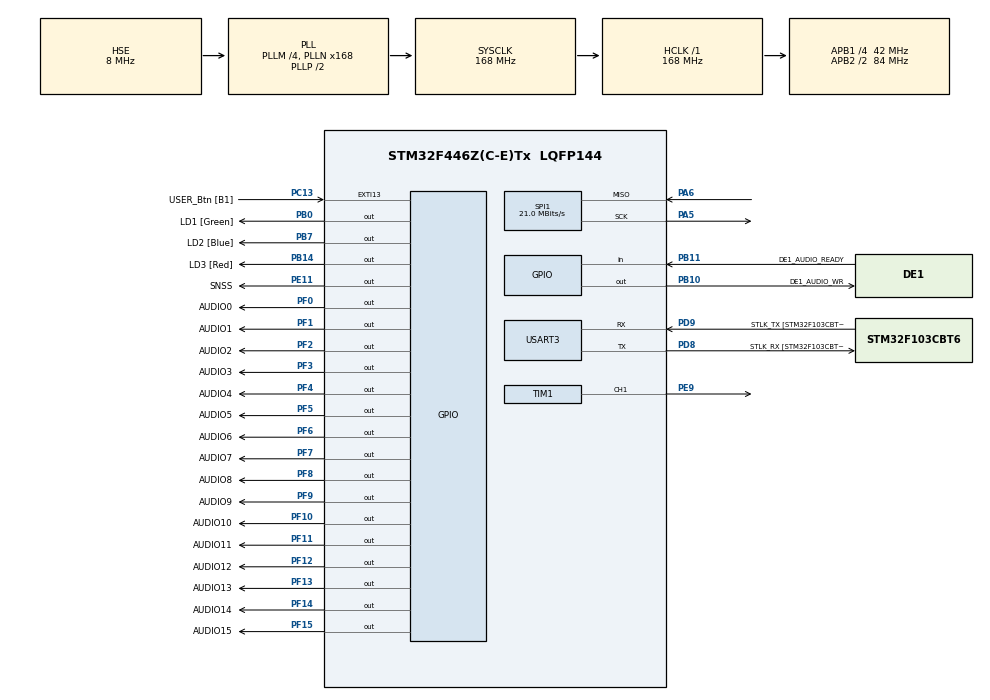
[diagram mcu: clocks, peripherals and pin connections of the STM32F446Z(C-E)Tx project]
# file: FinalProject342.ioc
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Mcu.Family=STM32F4
Mcu.Name=STM32F446Z(C-E)Tx
Mcu.Package=LQFP144
NVIC.PriorityGroup=NVIC_PRIORITYGROUP_4
PA10.GPIO_Label=USB_ID
PA10.Signal=USB_OTG_FS_ID
PA11.GPIO_Label=USB_DM
PA11.Signal=USB_OTG_FS_DM
PA12.GPIO_Label=USB_DP
PA12.Signal=USB_OTG_FS_DP
PA13.GPIO_Label=TMS
PA13.Mode=Serial_Wire
PA13.Signal=SYS_JTMS-SWDIO
PA14.GPIO_Label=TCK
PA14.Mode=Serial_Wire
PA14.Signal=SYS_JTCK-SWCLK
PA5.Mode=RX_Only_Simplex_Unidirect_Master
PA5.Signal=SPI1_SCK
PA6.Mode=RX_Only_Simplex_Unidirect_Master
PA6.Signal=SPI1_MISO
PA8.GPIO_Label=USB_SOF [TP1]
PA8.Signal=USB_OTG_FS_SOF
PA9.GPIO_Label=USB_VBUS
PA9.Signal=USB_OTG_FS_VBUS
PB0.GPIO_Label=LD1 [Green]
PB0.Signal=GPIO_Output
PB10.GPIO_Label=DE1_AUDIO_WR
PB10.GPIO_ModeDefaultOutputPP=GPIO_MODE_OUTPUT_OD
PB10.GPIO_PuPd=GPIO_NOPULL
PB10.GPIO_Speed=GPIO_SPEED_FREQ_VERY_HIGH
PB10.Signal=GPIO_Output
PB11.GPIO_Label=DE1_AUDIO_READY
PB11.Signal=GPIO_Input
PB14.GPIO_Label=LD3 [Red]
PB14.Signal=GPIO_Output
PB7.GPIO_Label=LD2 [Blue]
PB7.Signal=GPIO_Output
PC13.GPIO_Label=USER_Btn [B1]
PC13.Signal=GPXTI13
PC14-OSC32_IN.Mode=LSE-External-Oscillator
PC14-OSC32_IN.Signal=RCC_OSC32_IN
PC15-OSC32_OUT.Mode=LSE-External-Oscillator
PC15-OSC32_OUT.Signal=RCC_OSC32_OUT
PD8.GPIO_Label=STLK_RX [STM32F103CBT6_PA3]
PD8.Mode=Asynchronous
PD8.Signal=USART3_TX
PD9.GPIO_Label=STLK_TX [STM32F103CBT6_PA2]
PD9.Mode=Asynchronous
PD9.Signal=USART3_RX
PE11.GPIO_Label=SNSS
PE11.GPIO_ModeDefaultOutputPP=GPIO_MODE_OUTPUT_OD
PE11.GPIO_PuPd=GPIO_NOPULL
PE11.GPIO_Speed=GPIO_SPEED_FREQ_LOW
PE11.Signal=GPIO_Output
PE9.Signal=S_TIM1_CH1
PF0.GPIO_Label=AUDIO0
PF0.GPIO_ModeDefaultOutputPP=GPIO_MODE_OUTPUT_OD
PF0.GPIO_PuPd=GPIO_NOPULL
PF0.GPIO_Speed=GPIO_SPEED_FREQ_VERY_HIGH
PF0.Signal=GPIO_Output
PF1.GPIO_Label=AUDIO1
PF1.GPIO_ModeDefaultOutputPP=GPIO_MODE_OUTPUT_OD
PF1.GPIO_PuPd=GPIO_NOPULL
PF1.GPIO_Speed=GPIO_SPEED_FREQ_VERY_HIGH
PF1.Signal=GPIO_Output
PF10.GPIO_Label=AUDIO10
PF10.GPIO_ModeDefaultOutputPP=GPIO_MODE_OUTPUT_OD
PF10.GPIO_PuPd=GPIO_NOPULL
PF10.GPIO_Speed=GPIO_SPEED_FREQ_VERY_HIGH
PF10.Signal=GPIO_Output
PF11.GPIO_Label=AUDIO11
PF11.GPIO_ModeDefaultOutputPP=GPIO_MODE_OUTPUT_OD
PF11.GPIO_PuPd=GPIO_NOPULL
PF11.GPIO_Speed=GPIO_SPEED_FREQ_VERY_HIGH
PF11.Signal=GPIO_Output
PF12.GPIO_Label=AUDIO12
PF12.GPIO_ModeDefaultOutputPP=GPIO_MODE_OUTPUT_OD
PF12.GPIO_PuPd=GPIO_NOPULL
PF12.GPIO_Speed=GPIO_SPEED_FREQ_VERY_HIGH
PF12.Signal=GPIO_Output
PF13.GPIO_Label=AUDIO13
PF13.GPIO_ModeDefaultOutputPP=GPIO_MODE_OUTPUT_OD
PF13.GPIO_PuPd=GPIO_NOPULL
PF13.GPIO_Speed=GPIO_SPEED_FREQ_VERY_HIGH
PF13.Signal=GPIO_Output
PF14.GPIO_Label=AUDIO14
PF14.GPIO_ModeDefaultOutputPP=GPIO_MODE_OUTPUT_OD
PF14.GPIO_PuPd=GPIO_NOPULL
PF14.GPIO_Speed=GPIO_SPEED_FREQ_VERY_HIGH
PF14.Signal=GPIO_Output
PF15.GPIO_Label=AUDIO15
PF15.GPIO_ModeDefaultOutputPP=GPIO_MODE_OUTPUT_OD
PF15.GPIO_PuPd=GPIO_NOPULL
PF15.GPIO_Speed=GPIO_SPEED_FREQ_VERY_HIGH
PF15.Signal=GPIO_Output
PF2.GPIO_Label=AUDIO2
PF2.GPIO_ModeDefaultOutputPP=GPIO_MODE_OUTPUT_OD
PF2.GPIO_PuPd=GPIO_NOPULL
PF2.GPIO_Speed=GPIO_SPEED_FREQ_VERY_HIGH
PF2.Signal=GPIO_Output
PF3.GPIO_Label=AUDIO3
PF3.GPIO_ModeDefaultOutputPP=GPIO_MODE_OUTPUT_OD
PF3.GPIO_PuPd=GPIO_NOPULL
PF3.GPIO_Speed=GPIO_SPEED_FREQ_VERY_HIGH
PF3.Signal=GPIO_Output
PF4.GPIO_Label=AUDIO4
PF4.GPIO_ModeDefaultOutputPP=GPIO_MODE_OUTPUT_OD
PF4.GPIO_PuPd=GPIO_NOPULL
PF4.GPIO_Speed=GPIO_SPEED_FREQ_VERY_HIGH
PF4.Signal=GPIO_Output
PF5.GPIO_Label=AUDIO5
PF5.GPIO_ModeDefaultOutputPP=GPIO_MODE_OUTPUT_OD
PF5.GPIO_PuPd=GPIO_NOPULL
PF5.GPIO_Speed=GPIO_SPEED_FREQ_VERY_HIGH
PF5.Signal=GPIO_Output
PF6.GPIO_Label=AUDIO6
PF6.GPIO_ModeDefaultOutputPP=GPIO_MODE_OUTPUT_OD
PF6.GPIO_PuPd=GPIO_NOPULL
PF6.GPIO_Speed=GPIO_SPEED_FREQ_VERY_HIGH
PF6.Signal=GPIO_Output
PF7.GPIO_Label=AUDIO7
PF7.GPIO_ModeDefaultOutputPP=GPIO_MODE_OUTPUT_OD
PF7.GPIO_PuPd=GPIO_NOPULL
PF7.GPIO_Speed=GPIO_SPEED_FREQ_VERY_HIGH
PF7.Signal=GPIO_Output
PF8.GPIO_Label=AUDIO8
PF8.GPIO_ModeDefaultOutputPP=GPIO_MODE_OUTPUT_OD
PF8.GPIO_PuPd=GPIO_NOPULL
PF8.GPIO_Speed=GPIO_SPEED_FREQ_VERY_HIGH
PF8.Signal=GPIO_Output
PF9.GPIO_Label=AUDIO9
PF9.GPIO_ModeDefaultOutputPP=GPIO_MODE_OUTPUT_OD
PF9.GPIO_PuPd=GPIO_NOPULL
PF9.GPIO_Speed=GPIO_SPEED_FREQ_VERY_HIGH
PF9.Signal=GPIO_Output
PH0-OSC_IN.GPIO_Label=MCO [STM32F103CBT6_PA8]
PH0-OSC_IN.Mode=HSE-External-Clock-Source
PH0-OSC_IN.Signal=RCC_OSC_IN
PH1-OSC_OUT.Mode=HSE-External-Clock-Source
PH1-OSC_OUT.Signal=RCC_OSC_OUT
ProjectManager.HeapSize=0x200
ProjectManager.StackSize=0x400
ProjectManager.TargetToolchain=STM32CubeIDE
RCC.48MHZClocksFreq_Value=24000000
RCC.AHBFreq_Value=168000000
RCC.APB1CLKDivider=RCC_HCLK_DIV4
RCC.APB1Freq_Value=42000000
RCC.APB1TimFreq_Value=84000000
RCC.APB2CLKDivider=RCC_HCLK_DIV2
RCC.APB2Freq_Value=84000000
RCC.APB2TimFreq_Value=168000000
RCC.CortexFreq_Value=168000000
RCC.HCLKFreq_Value=168000000
RCC.HSE_VALUE=8000000
RCC.HSI_VALUE=16000000
RCC.PLLM=4
RCC.PLLMUL=RCC_PLL_MUL9
RCC.PLLN=168
RCC.PLLQ=7
RCC.PLLSourceVirtual=RCC_PLLSOURCE_HSE
RCC.PRESCALERUSB=RCC_USBCLKSOURCE_PLL_DIV1_5
RCC.SYSCLKFreq_VALUE=168000000
RCC.SYSCLKSource=RCC_SYSCLKSOURCE_PLLCLK
RCC.SYSCLKSourceVirtual=RCC_SYSCLKSOURCE_PLLCLK
RCC.USBFreq_Value=48000000
RCC.VCOOutputFreq_Value=336000000
SH.S_TIM1_CH1.0=TIM1_CH1,PWM Generation1 CH1
SPI1.BaudRatePrescaler=SPI_BAUDRATEPRESCALER_4
SPI1.CalculateBaudRate=21.0 MBits/s
SPI1.DataSize=SPI_DATASIZE_8BIT
SPI1.Direction=SPI_DIRECTION_2LINES_RXONLY
SPI1.FirstBit=SPI_FIRSTBIT_MSB
SPI1.Mode=SPI_MODE_MASTER
SPI1.VirtualType=VM_MASTER
TIM1.AutoReloadPreload=TIM_AUTORELOAD_PRELOAD_ENABLE
TIM1.Channel-PWM\ Generation1\ CH1=TIM_CHANNEL_1
TIM1.Period=5
TIM1.Pulse-PWM\ Generation1\ CH1=10
USART3.VirtualMode=VM_ASYNC
VP_TIM1_VS_ClockSourceINT.Mode=Internal
board=NUCLEO-F446ZE

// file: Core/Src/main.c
/* USER CODE BEGIN Header */
/**
  ******************************************************************************
  * @file           : main.c
  * @brief          : Main program body
  ******************************************************************************
  * @attention
  *
  * Copyright (c) 2023 STMicroelectronics.
  * All rights reserved.
  *
  * This software is licensed under terms that can be found in the LICENSE file
  * in the root directory of this software component.
  * If no LICENSE file comes with this software, it is provided AS-IS.
  *
  ******************************************************************************
  */
/* USER CODE END Header */
#include "main.h"

/* USER CODE BEGIN Includes */
#include <stdio.h>
#include <string.h>
//#include "usb_host.h"
//#include "fatfs.h"
//#include "usb_conf.h"
/* USER CODE END Includes */

SPI_HandleTypeDef hspi1;

TIM_HandleTypeDef htim1;

UART_HandleTypeDef huart3;

/* USER CODE BEGIN PV */
static const uint16_t ding_pcm[7988] =
{
    0x0000, 0x0000, 0x0000, 0x0000, 0x0001, 0xFFFE, 0x0002, 0xFFFE, 0x0001, 0x0000, 0x0001, 0xFFFD, 0x0003, 0xFFFE, 0x0001, 0x0000, 0xFFFF, 0x0001, 0x0000, 0x0000, 0x0000, 0x0000, 0xFFFF, 0x0002, 0xFFFE,
    0x0003, 0xFFFD, 0x0002, 0xFFFE, 0x0002, 0xFFFE, 0x0002, 0xFFFF, 0xFFFF, 0x0003, 0xFFFC, 0x0003, 0xFFFF, 0x0000, 0x0000, 0x0001, 0xFFFE, 0x0002, 0xFFFE, 0x0002, 0xFFFF, 0x0000, 0x0000, 0xFFFF, 0x0002,
    0xFFFE, 0x0002, 0xFFFE, 0x0001, 0x0001, 0xFFFE, 0x0002, 0xFFFE, 0x0002, 0xFFFE, 0x0003, 0xFFFC, 0x0004, 0xFFFD, 0x0001, 0x0001, 0xFFFE, 0x0002, 0xFFFF, 0x0000, 0x0000, 0x0001, 0xFFFE, 0x0003, 0xFFFD,
    0x0002, 0xFFFF, 0x0001, 0xFFFF, 0x0000, 0x0001, 0xFFFF, 0x0001, 0xFFFF, 0x0000, 0x0001, 0xFFFF, 0x0001, 0xFFFF, 0x0001, 0xFFFE, 0x0002, 0x0000, 0xFFFE, 0x0003, 0xFFFC, 0x0004, 0xFFFD, 0x0002, 0xFFFF,
    0x0000, 0x0001, 0xFFFE, 0x0003, 0xFFFD, 0x0002, 0xFFFF, 0x0001, 0xFFFF, 0x0000, 0x0001, 0xFFFF, 0x0001, 0xFFFF, 0x0000, 0x0001, 0xFFFF, 0x0001, 0xFFFF, 0x0001, 0xFFFF, 0x0001, 0xFFFE, 0x0003, 0xFFFD,
    0x0002, 0x0000, 0xFFFE, 0x0003, 0xFFFD, 0x0003, 0xFFFD, 0x0004, 0xFFFB, 0x0004, 0xFFFE, 0x0001, 0xFFFF, 0x0000, 0x0001, 0xFFFF, 0x0001, 0xFFFF, 0xFFFF, 0x0003, 0xFFFE, 0x0001, 0xFFFF, 0x0000, 0x0001,
    0x0000, 0xFFFF, 0x0001, 0xFFFE, 0x0003, 0xFFFE, 0x0000, 0x0001, 0xFFFF, 0x0000, 0x0002, 0xFFFD, 0x0002, 0xFFFF, 0x0001, 0xFFFF, 0x0001, 0xFFFF, 0x0001, 0xFFFF, 0x0001, 0x0000, 0xFFFF, 0x0002, 0xFFFE,
    0x0002, 0xFFFF, 0xFFFF, 0x0002, 0xFFFE, 0x0002, 0xFFFE, 0x0002, 0xFFFF, 0x0000, 0x0001, 0xFFFE, 0x0002, 0xFFFF, 0x0000, 0x0001, 0xFFFE, 0x0002, 0xFFFE, 0x0001, 0x0000, 0xFFFF, 0x0002, 0xFFFE, 0x0001,
    0x0001, 0xFFFD, 0x0004, 0xFFFB, 0x0005, 0xFFFB, 0x0005, 0xFFFB, 0x0005, 0xFFFB, 0x0005, 0xFFFC, 0x0003, 0xFFFD, 0x0003, 0xFFFD, 0x0003, 0xFFFE, 0x0001, 0x0000, 0x0000, 0x0000, 0x0001, 0xFFFF, 0x0002,
    0xFFFF, 0x0001, 0xFFFF, 0x0001, 0xFFFE, 0x0002, 0xFFFE, 0x0003, 0xFFFD, 0x0003, 0xFFFC, 0x0006, 0xFFFB, 0x0004, 0xFFFC, 0x0003, 0xFFFF, 0x0000, 0x0000, 0x0001, 0xFFFE, 0x0002, 0xFFFE, 0x0000, 0x0002,
    0xFFFC, 0x0003, 0xFFFD, 0x0004, 0xFFFB, 0x0004, 0xFFFD, 0x0003, 0xFFFD, 0x0002, 0x0000, 0xFFFF, 0x0000, 0xFFFF, 0x0002, 0xFFFD, 0x0003, 0xFFFC, 0x0004, 0xFFFC, 0x0002, 0xFFFF, 0x0001, 0x0001, 0xFFFE,
    0x0002, 0xFFFE, 0x0001, 0xFFFE, 0x0001, 0xFFFF, 0x0001, 0xFFFF, 0x0001, 0xFFFE, 0x0003, 0xFFFE, 0xFFFF, 0x0001, 0xFFFF, 0x0000, 0x0001, 0xFFFE, 0x0003, 0xFFFE, 0x0000, 0x0001, 0xFFFF, 0x0001, 0xFFFF,
    0x0000, 0x0002, 0xFFFE, 0x0000, 0x0000, 0x0000, 0x0000, 0x0000, 0x0000, 0x0002, 0x0000, 0x0001, 0xFFFF, 0x0001, 0xFFFF, 0x0001, 0x0000, 0x0001, 0xFFFF, 0x0001, 0x0002, 0xFFFD, 0x0003, 0xFFFF, 0x0001,
    0x0002, 0xFFFF, 0x0004, 0xFFFD, 0x0002, 0x0001, 0xFFFE, 0x0004, 0xFFFC, 0x0003, 0x0000, 0x0000, 0x0000, 0x0001, 0xFFFD, 0x0003, 0xFFFD, 0x0002, 0x0000, 0xFFFE, 0x0001, 0xFFFF, 0x0001, 0xFFFF, 0x0000,
    0xFFFF, 0xFFFF, 0x0001, 0xFFFE, 0x0000, 0x0000, 0x0001, 0xFFFF, 0x0002, 0xFFFF, 0x0002, 0x0000, 0xFFFF, 0x0002, 0xFFFE, 0x0003, 0xFFFE, 0x0001, 0x0000, 0x0002, 0xFFFE, 0x0003, 0xFFFE, 0x0001, 0x0000,
    0xFFFF, 0x0001, 0x0000, 0xFFFF, 0xFFFE, 0x0002, 0xFFFF, 0x0001, 0xFFFF, 0xFFFE, 0x0001, 0xFFFF, 0x0001, 0xFFFF, 0xFFFE, 0x0002, 0xFFFC, 0x0003, 0xFFFC, 0x0001, 0x0000, 0xFFFD, 0x0002, 0xFFFE, 0x0002,
    0xFFFF, 0x0001, 0xFFFC, 0x0006, 0xFFFA, 0x0004, 0xFFFF, 0xFFFE, 0x0005, 0xFFFB, 0x0006, 0xFFFC, 0x0005, 0xFFFF, 0x0000, 0x0002, 0xFFFC, 0x0003, 0xFFFF, 0xFFFE, 0x0003, 0xFFFB, 0x0004, 0xFFFD, 0x0000,
    0xFFFF, 0x0002, 0xFFFB, 0x0004, 0xFFFA, 0x0002, 0xFFFE, 0xFFFE, 0x0002, 0xFFFD, 0x0001, 0xFFFE, 0x0001, 0xFFFE, 0xFFFF, 0xFFFE, 0x0002, 0x0001, 0xFFFF, 0x0001, 0x0002, 0xFFFD, 0x0002, 0x0003, 0xFFFC,
    0x0005, 0xFFFB, 0x0005, 0xFFFD, 0x0003, 0xFFFD, 0x0002, 0xFFFE, 0x0002, 0x0002, 0x0001, 0x0000, 0x0003, 0xFFFF, 0x0001, 0xFFFD, 0x0002, 0x0000, 0x0002, 0xFFFC, 0x0005, 0xFFFC, 0x0004, 0xFFFC, 0x0004,
    0xFFFE, 0x0004, 0xFFFF, 0x0001, 0x0000, 0x0000, 0x0000, 0x0000, 0x0002, 0xFFFD, 0x0002, 0x0001, 0x0001, 0x0001, 0xFFFF, 0xFFFF, 0x0000, 0xFFFF, 0x0001, 0xFFFE, 0x0000, 0x0002, 0x0001, 0x0001, 0xFFFE,
    0x0001, 0xFFFF, 0x0000, 0x0000, 0x0002, 0xFFFF, 0xFFFD, 0xFFFF, 0x0004, 0xFFFC, 0x0004, 0xFFFC, 0x0005, 0xFFFC, 0x0003, 0xFFFF, 0x0000, 0xFFFE, 0x0000, 0x0003, 0xFFFA, 0x0003, 0xFFFC, 0x0001, 0xFFFE,
    0x0001, 0xFFFD, 0x0002, 0xFFFE, 0xFFFF, 0xFFFC, 0x0004, 0xFFFF, 0xFFFF, 0x0001, 0xFFFE, 0x0003, 0xFFFF, 0x0000, 0xFFFD, 0x0000, 0xFFFC, 0x0001, 0x0000, 0xFFFF, 0x0001, 0xFFFF, 0x0003, 0xFFFF, 0x0004,
    0xFFFE, 0x0001, 0x0001, 0xFFFB, 0x0004, 0xFFFE, 0x0000, 0x0001, 0x0000, 0xFFFE, 0x0001, 0x0001, 0x0001, 0x0000, 0x0001, 0xFFFE, 0x0004, 0xFFFB, 0x0004, 0xFFFE, 0x0000, 0x0003, 0xFFFD, 0x0003, 0xFFFE,
    0x0000, 0xFFFF, 0xFFFF, 0xFFFF, 0xFFFF, 0x0000, 0xFFFE, 0x0001, 0x0001, 0xFFFF, 0xFFFD, 0x0003, 0xFFFD, 0x0000, 0xFFFF, 0x0001, 0x0000, 0xFFFF, 0x0002, 0xFFFE, 0xFFFF, 0xFFFF, 0xFFFC, 0x0004, 0xFFFC,
    0x0004, 0xFFFE, 0x0002, 0xFFFF, 0xFFFF, 0x0000, 0xFFFE, 0xFFFF, 0x0001, 0xFFFF, 0x0002, 0xFFFB, 0x0003, 0xFFFC, 0x0002, 0xFFFD, 0x0002, 0xFFFD, 0xFFFE, 0x0001, 0x0001, 0x0001, 0x0001, 0x0002, 0xFFFF,
    0x0000, 0x0002, 0xFFFF, 0xFFFF, 0x0002, 0xFFFD, 0x0002, 0x0000, 0xFFFF, 0xFFFE, 0x0003, 0xFFFB, 0x0006, 0xFFFA, 0x0002, 0xFFFB, 0x0004, 0xFFFA, 0x0000, 0x0002, 0xFFFE, 0x0002, 0xFFFE, 0x0000, 0x0003,
    0xFFFF, 0x0001, 0x0000, 0xFFFD, 0x0002, 0xFFFF, 0x0001, 0x0000, 0xFFFE, 0x0001, 0xFFFF, 0x0000, 0xFFFE, 0xFFFF, 0xFFFF, 0x0000, 0xFFFF, 0xFFFF, 0x0002, 0xFFFD, 0x0000, 0xFFFD, 0x0001, 0xFFFD, 0x0002,
    0xFFFF, 0x0001, 0x0001, 0xFFFD, 0x0004, 0xFFFC, 0xFFFE, 0x0001, 0xFFFE, 0x0000, 0xFFFE, 0xFFFF, 0x0002, 0x0000, 0x0000, 0x0001, 0xFFFF, 0x0003, 0xFFFF, 0x0003, 0x0000, 0x0001, 0xFFFD, 0x0000, 0xFFFF,
    0x0001, 0xFFFF, 0x0001, 0xFFFE, 0x0001, 0xFFFE, 0x0004, 0xFFFF, 0x0001, 0xFFFF, 0xFFFE, 0x0002, 0x0000, 0xFFFF, 0x0000, 0xFFFE, 0x0000, 0x0000, 0x0000, 0x0001, 0x0000, 0xFFFE, 0x0000, 0x0000, 0x0000,
    0xFFFF, 0xFFFF, 0xFFFD, 0x0003, 0xFFFD, 0x0001, 0xFFFE, 0x0001, 0xFFFC, 0x0001, 0x0000, 0xFFFC, 0x0001, 0xFFFE, 0x0000, 0x0003, 0xFFFD, 0x0002, 0xFFFF, 0x0001, 0xFFFC, 0x0003, 0xFFFE, 0x0000, 0x0003,
    0xFFFC, 0x0003, 0xFFFD, 0x0004, 0xFFFC, 0xFFFB, 0x0004, 0xFFFE, 0x0002, 0x0000, 0x0007, 0xFFFC, 0xFFFE, 0xFFFF, 0x0001, 0x0001, 0x0005, 0x0003, 0x0001, 0xFFFF, 0x0005, 0xFFFD, 0x0007, 0xFFF6, 0x0003,
    0x0001, 0x0004, 0xFFFA, 0x0000, 0x0005, 0x0004, 0x0001, 0x0001, 0xFFFD, 0x0009, 0xFFFE, 0xFFFE, 0x0001, 0xFFF7, 0x000B, 0xFFF5, 0x000A, 0xFFF9, 0xFFFA, 0xFFFB, 0x0007, 0xFFFC, 0x0005, 0xFFFA, 0x0007,
    0xFFF4, 0x0001, 0x000C, 0xFF73, 0xFF92, 0xFF77, 0x001C, 0xFEED, 0xFFAA, 0xFFDC, 0xFFA5, 0x0031, 0xFF34, 0xFFC3, 0xFF52, 0xFFC3, 0xFED8, 0xFFFB, 0xFF90, 0xFF25, 0xFF6D, 0xFEE3, 0xFFA0, 0xFEA2, 0xFFED,
    0xFF21, 0xFF4F, 0xFFA4, 0xFF7A, 0xFFA8, 0xFF48, 0xFFFF, 0xFF71, 0xFF1C, 0x0004, 0xFF7F, 0xFF7D, 0xFF9B, 0xFF74, 0xFF9F, 0xFF7C, 0xFF7A, 0xFE8E, 0x0017, 0xFFAF, 0xFF90, 0xFF52, 0x000A, 0xFFF6, 0xFF59,
    0xFF78, 0xFFBF, 0x0004, 0xFE94, 0x0028, 0xFF7A, 0xFF91, 0xFF76, 0xFFA7, 0xFF55, 0xFFCF, 0xFF29, 0xFFBA, 0x0063, 0xFF38, 0xFF15, 0x000D, 0x0002, 0xFF79, 0xFF41, 0xFFAC, 0x0046, 0xFE81, 0x001C, 0xFEE4,
    0x0027, 0xFF8A, 0xFF78, 0xFF4A, 0xFFAB, 0xFEFF, 0xFFBC, 0xFF8A, 0xFF40, 0x0019, 0xFFD1, 0xFF7E, 0xFF22, 0xFEFC, 0xFF3D, 0x00C9, 0xFE89, 0xFF31, 0xFEE2, 0x0128, 0xFE70, 0x0010, 0xFEC3, 0x01FC, 0xFD8A,
    0x002A, 0xFE97, 0x0096, 0xFEAC, 0xFF9F, 0xFF4B, 0xFED0, 0x0068, 0xFE72, 0x00D0, 0xFEF7, 0x00B5, 0xFE16, 0x01CB, 0xFCDE, 0x01AF, 0xFCE4, 0x02DA, 0xFBFC, 0x0418, 0xFAF5, 0x04E9, 0xFA28, 0x0387, 0xFBB4,
    0x04FE, 0xF9F1, 0x02A3, 0xFE21, 0x00CE, 0xFDBC, 0x06FC, 0x0844, 0xD05E, 0x2FCE, 0x03FF, 0xF405, 0xDB35, 0x24E3, 0xECAF, 0x0E47, 0x0B09, 0xDDF7, 0x1F19, 0xEDE2, 0xFF7D, 0x1697, 0xDBA4, 0x1C27, 0x02AF,
    0xC562, 0x51D8, 0xC22D, 0x2028, 0xF44D, 0xF05A, 0x34EE, 0xDA01, 0xDE82, 0x448B, 0xE894, 0xD11F, 0x28E8, 0xF801, 0x1416, 0xE83E, 0xEF2E, 0x3378, 0xE1A7, 0xDB36, 0x40E8, 0xC929, 0x1EB1, 0xF75C, 0xEDBA,
    0x23F8, 0xF612, 0xE5A1, 0x1B0D, 0x026B, 0xE66F, 0x0E00, 0xEC3A, 0x205E, 0xFB38, 0xD6D7, 0x3B1E, 0xF2DB, 0xD3F4, 0x2E16, 0xE386, 0x0BC8, 0xF625, 0xF72B, 0x1D46, 0xFAB6, 0xDF74, 0x2965, 0xEE17, 0xEF52,
    0x228B, 0xD258, 0x1EE3, 0x0389, 0xD544, 0x3273, 0xF084, 0xF100, 0x1F25, 0xDA9A, 0x21D8, 0xEB74, 0xE53F, 0x2FFF, 0xE949, 0xED27, 0x2CC4, 0xE1B9, 0x0E49, 0xFDC3, 0xE62C, 0x2771, 0xE12E, 0xF56C, 0x255C,
    0xDEE1, 0x0E51, 0x0DBF, 0xE2A9, 0x1D0B, 0xECA1, 0xF4C9, 0x2350, 0xE7A8, 0xEA56, 0x310B, 0xD49C, 0x2173, 0xF4EB, 0xE5CE, 0x3117, 0xDEE2, 0xE6D7, 0x2B8E, 0xEADB, 0xF663, 0x1A3F, 0xE21E, 0x2CB6, 0xE4E5,
    0xE55C, 0x3651, 0xDCF8, 0xEBC2, 0x2B6B, 0xDB1F, 0x218E, 0xEF9D, 0xEBD2, 0x3079, 0xE567, 0xEB06, 0x231B, 0xE563, 0x02B5, 0x0D4E, 0xDD34, 0x2FF8, 0xECDD, 0xE76C, 0x324F, 0xDF56, 0xFA29, 0x0F8F, 0xE36E,
    0x2809, 0xE21C, 0xF748, 0x2D2B, 0xDE39, 0xF853, 0x24BA, 0xDC2A, 0x0E3C, 0xFC03, 0xE9C7, 0x2CE9, 0xE127, 0xF544, 0x30A6, 0xD45E, 0x0E40, 0x0974, 0xDDE7, 0x2B54, 0xDBE3, 0xF471, 0x31EB, 0xDC63, 0xFF24,
    0x2474, 0xD5DA, 0x2192, 0xECC5, 0xE6A6, 0x36B3, 0xD1A5, 0xFE07, 0x2E19, 0xD393, 0x1AA9, 0xF7F9, 0xECD4, 0x2DAA, 0xD822, 0xF32F, 0x2C34, 0xDCBC, 0x037A, 0x16FC, 0xDEB1, 0x2AC8, 0xE72E, 0xECB8, 0x2C24,
    0xDD27, 0xF55A, 0x23F3, 0xDB40, 0x1F25, 0xFCDE, 0xE3C3, 0x2C55, 0xE84C, 0xEC9E, 0x1F26, 0xE41A, 0x0886, 0x0BE8, 0xDEE1, 0x3293, 0xE4CF, 0xEFFB, 0x22CE, 0xE714, 0xFC2C, 0x1793, 0xDAB7, 0x1CD1, 0xF9F3,
    0xE914, 0x3240, 0xDC7C, 0xFFA8, 0x23E9, 0xCDCD, 0x192A, 0x0556, 0xD1EB, 0x3DF0, 0xDAAB, 0xFD93, 0x2AE2, 0xD47D, 0x0FF0, 0x0A8D, 0xD37F, 0x333C, 0xE4A3, 0xE5CB, 0x40B1, 0xCFBF, 0x04D2, 0x22D5, 0xD2FD,
    0x244A, 0xF1AF, 0xE32A, 0x342F, 0xCFC9, 0x074B, 0x1EA8, 0xDC93, 0x162B, 0x0BC2, 0xDBC4, 0x234F, 0xEC5C, 0xEAD4, 0x273B, 0xDAA4, 0x0EB3, 0x12DA, 0xE18B, 0x23AE, 0xEDFA, 0xED70, 0x2425, 0xE276, 0xFA36,
    0x1CF2, 0xE2F8, 0x0C40, 0x0A63, 0xE8FB, 0x23FF, 0xE394, 0xFD0C, 0x1F89, 0xD507, 0x0A4A, 0x1146, 0xE064, 0x1FB3, 0xF6E0, 0xF392, 0x2360, 0xDF5E, 0xFFCC, 0x146F, 0xD95C, 0x1DC5, 0xFC20, 0xE31A, 0x3639,
    0xDB86, 0xFDFE, 0x26D5, 0xCE84, 0x1830, 0x042E, 0xDFD4, 0x27EC, 0xE074, 0xFFE8, 0x28C1, 0xCF49, 0x1895, 0x15B2, 0xCD43, 0x26B3, 0xEE23, 0xEE49, 0x263E, 0xDBBC, 0x10CD, 0x1544, 0xDA60, 0x223C, 0xF215,
    0xEA2C, 0x23E4, 0xDF29, 0x012B, 0x1A60, 0xE4D6, 0x0A5B, 0x0C9F, 0xE660, 0x1B48, 0xEC5E, 0xF86F, 0x1CF2, 0xD949, 0x0C21, 0x13F2, 0xE136, 0x1895, 0xFCDE, 0xF1EC, 0x18FF, 0xE4BC, 0x01F8, 0x10AF, 0xE1DF,
    0x164F, 0x0220, 0xEA94, 0x22A6, 0xE811, 0xF8A9, 0x1DDB, 0xDC07, 0x0BCF, 0x0965, 0xE560, 0x21B9, 0xE9F8, 0xFB7E, 0x229B, 0xD975, 0x0B87, 0x13B0, 0xD8A7, 0x1ABA, 0xF83E, 0xEE0F, 0x23A8, 0xE298, 0x07FF,
    0x15DA, 0xD958, 0x1A02, 0xFC1C, 0xE47B, 0x229C, 0xE966, 0xFCAB, 0x1D80, 0xE3DD, 0x0944, 0x0A6E, 0xE5A7, 0x1922, 0xF03A, 0xF544, 0x1C8C, 0xE5A0, 0x0246, 0x18B9, 0xE192, 0x11EC, 0x01E3, 0xECEA, 0x1540,
    0xECD9, 0xFD0C, 0x1382, 0xEB49, 0x09AD, 0x0D19, 0xE823, 0x18F4, 0xF303, 0xF0AF, 0x17B0, 0xEBA6, 0xFFDB, 0x11A6, 0xE822, 0x17A2, 0xF6C6, 0xF4B4, 0x1B5B, 0xE482, 0x0275, 0x0F9C, 0xE925, 0x0BED, 0x036B,
    0xEF8F, 0x1ADC, 0xEB4D, 0x0418, 0x10AA, 0xE0CF, 0x10DD, 0x0013, 0xE917, 0x1CD3, 0xF018, 0xFE49, 0x158A, 0xE9CF, 0x090D, 0x0265, 0xEDAB, 0x115A, 0xF58D, 0xF569, 0x1A10, 0xEAF2, 0x0147, 0x14A4, 0xE76C,
    0x09C8, 0x0508, 0xEC2E, 0x136E, 0xF119, 0xFD60, 0x1384, 0xED30, 0x0524, 0x105D, 0xE6D0, 0x0CB7, 0x01C2, 0xEAAC, 0x148F, 0xF50B, 0xFBF6, 0x1305, 0xED2A, 0x0AB2, 0x03E9, 0xEB22, 0x1609, 0xF10E, 0xF92A,
    0x12D8, 0xEFFC, 0x01E3, 0x0D71, 0xEE62, 0x0FAA, 0xF757, 0xF9B9, 0x0F2F, 0xEB18, 0x07E6, 0x0632, 0xEECD, 0x1162, 0xFE07, 0xF5B9, 0x1053, 0xEFE7, 0x0482, 0x01CC, 0xF236, 0x0C3F, 0xFDEC, 0xF546, 0x162A,
    0xEFAD, 0x0103, 0x0BCC, 0xEE75, 0x0727, 0x009F, 0xF73F, 0x092D, 0xFA9B, 0xFCE0, 0x0E64, 0xF1C7, 0x0529, 0x06D3, 0xEF87, 0x0638, 0x037B, 0xEF99, 0x109E, 0xFA71, 0xFC0A, 0x0C1D, 0xF6EF, 0x00B6, 0x0669,
    0xEE65, 0x0B96, 0x00AE, 0xEFB4, 0x1506, 0xF57D, 0xFC40, 0x0D87, 0xF235, 0x0162, 0x06A2, 0xEE7D, 0x0F71, 0xF864, 0xF8EB, 0x1009, 0xF4A9, 0x010F, 0x0B8B, 0xF023, 0x082F, 0xFE93, 0xF536, 0x0B94, 0xF57B,
    0x033E, 0x0777, 0xF5DC, 0x0961, 0xFE3E, 0xF46F, 0x0BD4, 0xF406, 0x0242, 0x0486, 0xF727, 0x07FF, 0xFF46, 0xF809, 0x0C13, 0xF4D5, 0x00CE, 0x0589, 0xF345, 0x057F, 0x0147, 0xF8D9, 0x084A, 0xFD91, 0xFBE5,
    0x0AB4, 0xF403, 0x01DF, 0x0423, 0xF55E, 0x0408, 0x06CD, 0xF47E, 0x0CC2, 0xFB65, 0xFAC6, 0x08A8, 0xF5AB, 0xFF2E, 0x0817, 0xF418, 0x0676, 0x0465, 0xF356, 0x0DBD, 0xF939, 0xFB55, 0x0A48, 0xF5E0, 0xFE1C,
    0x08BD, 0xF2F9, 0x08E4, 0xFEE3, 0xF99B, 0x0C53, 0xF86C, 0xFBA6, 0x0952, 0xF28A, 0x0397, 0x03A0, 0xF607, 0x0A69, 0xFC62, 0xFD37, 0x06B4, 0xF61B, 0x0163, 0x04DE, 0xF41A, 0x0930, 0xFD26, 0xFB37, 0x08AC,
    0xF933, 0x0104, 0x04BF, 0xF5A8, 0x08C6, 0xFAFC, 0xFA13, 0x0980, 0xF9AD, 0xFE91, 0x08C1, 0xF828, 0x030E, 0x018B, 0xF44A, 0x09F6, 0xF6F5, 0xFF0C, 0x09C4, 0xF5AF, 0x046F, 0x061E, 0xF2A5, 0x0903, 0xFC31,
    0xF963, 0x0859, 0xF844, 0x008C, 0x0634, 0xF58F, 0x080C, 0x0157, 0xF4DF, 0x0D29, 0xF7F8, 0xFAFD, 0x07DB, 0xF6E0, 0x01C7, 0x059E, 0xF85E, 0x0818, 0xFC6C, 0xFA28, 0x0767, 0xF706, 0xFD4D, 0x0A79, 0xF4B7,
    0x0536, 0x055C, 0xF531, 0x0746, 0xFC06, 0xFCDB, 0x050A, 0xF7E8, 0x02C9, 0x04AA, 0xF4A3, 0x07F5, 0xFFD5, 0xF830, 0x0954, 0xFC46, 0xF987, 0x0641, 0xF6E7, 0x0482, 0xFF51, 0xF963, 0x0D2B, 0xF7AD, 0xFCC1,
    0x08E3, 0xF47B, 0xFFEC, 0x06CD, 0xF5B0, 0x0707, 0xFF35, 0xFBDB, 0x0932, 0xF51C, 0x02BC, 0x06A4, 0xF136, 0x0A0A, 0xFFAE, 0xF4AC, 0x0B60, 0xFB28, 0xFCE1, 0x07DA, 0xF890, 0x0409, 0xFFDF, 0xF576, 0x09FD,
    0xF9B3, 0xFA0D, 0x0DB3, 0xF78E, 0xFF43, 0x07EF, 0xF683, 0x0196, 0xFF7E, 0xFBF0, 0x0607, 0xFACA, 0xFFB0, 0x0788, 0xF628, 0x02B6, 0x04AE, 0xF55D, 0x0685, 0x0095, 0xF83E, 0x05D7, 0xFBEB, 0x0085, 0x03AF,
    0xF8F4, 0x0833, 0xFDAE, 0xF5A0, 0x09F5, 0xFA8D, 0xF9BA, 0x0B0C, 0xF985, 0x0107, 0x04F8, 0xF6EB, 0x0680, 0xFA3A, 0xFA64, 0x0C59, 0xF43B, 0x0240, 0x0A3A, 0xF154, 0x074A, 0x03F1, 0xF4B1, 0x09ED, 0xFAA2,
    0xFCA3, 0x06EB, 0xF398, 0x0881, 0x0222, 0xF321, 0x0F71, 0xFBF5, 0xF60B, 0x0BA6, 0xF6AF, 0xFDDD, 0x054F, 0xF91B, 0x0824, 0xFDBA, 0xFAA9, 0x0B29, 0xF4B7, 0xFE5C, 0x0956, 0xF3CF, 0x0441, 0x04B3, 0xF6F2,
    0x05FB, 0xFEE3, 0xFD1C, 0x057F, 0xF86A, 0x03E8, 0x011C, 0xF40A, 0x0891, 0xFEFD, 0xF657, 0x0B9D, 0xFDD7, 0xFB58, 0x0599, 0xF8C4, 0x01EA, 0xFF80, 0xF8AE, 0x0AD2, 0xFB35, 0xFB22, 0x0D75, 0xF3DC, 0xFF92,
    0x0941, 0xF2BF, 0x0685, 0x00FC, 0xF82E, 0x0906, 0xF711, 0x0225, 0x080B, 0xF044, 0x0ABF, 0x0332, 0xEE21, 0x0DB4, 0xFB57, 0xF7DB, 0x0D03, 0xF5D0, 0x0598, 0x0406, 0xF2AE, 0x0CCB, 0xF957, 0xF698, 0x10CA,
    0xF348, 0xFE39, 0x0DE7, 0xF0C1, 0x046F, 0x0463, 0xF5A6, 0x09B3, 0xF8DC, 0xFE21, 0x0A0A, 0xF16B, 0x0609, 0x0731, 0xF056, 0x0B52, 0x0225, 0xF3FF, 0x091B, 0xFADA, 0xFCA9, 0x0646, 0xF644, 0x091E, 0x0069,
    0xF45C, 0x0E72, 0xF829, 0xF82E, 0x0D07, 0xF51F, 0x004A, 0x0809, 0xF535, 0x0802, 0xFC60, 0xFAAD, 0x0B70, 0xF2A3, 0x0395, 0x0AC9, 0xEC16, 0x0AC3, 0x034E, 0xF135, 0x0E8F, 0xF978, 0xFE3E, 0x089C, 0xF138,
    0x08D9, 0x0192, 0xEF3C, 0x1355, 0xF959, 0xF562, 0x13C9, 0xF0B2, 0xFEF1, 0x0BE3, 0xEE33, 0x0BF5, 0xFE6C, 0xF4E5, 0x1225, 0xEF9E, 0x000E, 0x1025, 0xEA46, 0x08D9, 0x0915, 0xEBCC, 0x0ECD, 0xFB68, 0xF795,
    0x0F3B, 0xF0C3, 0x06FB, 0x07E1, 0xEBA9, 0x10AC, 0xFCB0, 0xF089, 0x1349, 0xF50C, 0xFBFD, 0x0EA6, 0xF0B5, 0x060C, 0x02E6, 0xF1A2, 0x10ED, 0xF51D, 0xFB7E, 0x121B, 0xEC18, 0x04F1, 0x0AC9, 0xEC91, 0x0CF7,
    0xFF1E, 0xF62C, 0x0F0E, 0xF18F, 0x02DC, 0x09B7, 0xEBB7, 0x0F9F, 0x0144, 0xEE91, 0x151B, 0xF3DD, 0xFA3B, 0x0FE1, 0xED94, 0x093F, 0x044F, 0xEF51, 0x1310, 0xF4AC, 0xF7D1, 0x152D, 0xEA28, 0x05AE, 0x0D75,
    0xE910, 0x0FAD, 0xFE3B, 0xF0C9, 0x14ED, 0xEFCB, 0x01C7, 0x1063, 0xE68D, 0x0F33, 0x03C2, 0xE938, 0x1838, 0xF596, 0xF5EF, 0x16C9, 0xEAB6, 0x05EE, 0x0A46, 0xE8E3, 0x138C, 0xFB81, 0xF155, 0x18D2, 0xEB10,
    0xFEF8, 0x1341, 0xE63B, 0x0D81, 0x047E, 0xED5C, 0x14E9, 0xF2EF, 0xFA6E, 0x12B8, 0xE8F2, 0x0A7C, 0x08B2, 0xE8FB, 0x152F, 0xF93D, 0xF2DC, 0x15D1, 0xECBB, 0x036E, 0x0C52, 0xE9ED, 0x10BC, 0xFBB3, 0xF138,
    0x17AC, 0xEE48, 0xFF34, 0x127E, 0xE6D1, 0x0C5A, 0x041A, 0xEC0F, 0x1686, 0xF3A2, 0xFB0B, 0x158D, 0xE691, 0x0AF4, 0x0929, 0xE556, 0x181C, 0xF8B5, 0xF115, 0x1A5F, 0xEA43, 0x022C, 0x0FAE, 0xE4F6, 0x1334,
    0xFFD2, 0xEB65, 0x1BC8, 0xED32, 0xFA7A, 0x1838, 0xE39C, 0x0D4B, 0x0A38, 0xE5FA, 0x17FF, 0xF59C, 0xF290, 0x1992, 0xE80E, 0x064A, 0x1129, 0xE378, 0x14C8, 0xFE7F, 0xEA0C, 0x1B50, 0xEDEF, 0xFC80, 0x156B,
    0xE571, 0x0E1B, 0x04A3, 0xE8EC, 0x198D, 0xF38D, 0xF71F, 0x187E, 0xE687, 0x0739, 0x0C08, 0xE66B, 0x1583, 0xFB8F, 0xF280, 0x1884, 0xE9E5, 0x02C6, 0x0EB1, 0xE414, 0x137D, 0xFF81, 0xEC6F, 0x1AAC, 0xEF09,
    0xFB8D, 0x144A, 0xE4FF, 0x0E06, 0x0619, 0xE866, 0x1A20, 0xF1D1, 0xF5B7, 0x1A97, 0xE4D8, 0x08FD, 0x0F08, 0xE356, 0x16A9, 0xF9DA, 0xEDBE, 0x1C3E, 0xE985, 0x0226, 0x14DA, 0xE11C, 0x1283, 0x026C, 0xE5A9,
    0x1DA6, 0xF0B5, 0xF70D, 0x1BF7, 0xE41C, 0x0A69, 0x0B31, 0xE390, 0x1929, 0xF803, 0xF0A6, 0x1CA2, 0xE769, 0x0194, 0x12E4, 0xE347, 0x134C, 0x0234, 0xEADA, 0x1A56, 0xEECC, 0xF9FD, 0x14BF, 0xE4DC, 0x0E38,
    0x083C, 0xE825, 0x191D, 0xF518, 0xF373, 0x1767, 0xE911, 0x06F7, 0x0CE5, 0xE7A1, 0x149C, 0xFA8A, 0xF08D, 0x198D, 0xEAD0, 0x019F, 0x128B, 0xE3C3, 0x1124, 0x0157, 0xEA8C, 0x1A3E, 0xF0B2, 0xFC2D, 0x16DE,
    0xE41D, 0x0CE9, 0x0703, 0xE532, 0x1A60, 0xF6AB, 0xF295, 0x1C45, 0xE731, 0x03DE, 0x1098, 0xE2AC, 0x1580, 0xFE56, 0xEC90, 0x1C5E, 0xEBA2, 0xFBF1, 0x1759, 0xE2FF, 0x0EB2, 0x0914, 0xE5ED, 0x1886, 0xF4D1,
    0xF34E, 0x190D, 0xE83A, 0x079F, 0x0F38, 0xE4FF, 0x1558, 0xFBDD, 0xEC7B, 0x1964, 0xEE07, 0xFE6D, 0x1460, 0xE771, 0x0D8B, 0x027B, 0xEA5F, 0x172A, 0xF291, 0xF962, 0x168E, 0xE7A0, 0x0855, 0x09B0, 0xE7FB,
    0x1543, 0xFA3F, 0xF45A, 0x1620, 0xEB1F, 0x02E5, 0x0D14, 0xE68B, 0x1306, 0xFF88, 0xEE72, 0x18BD, 0xEEA1, 0xFB8E, 0x1280, 0xE76E, 0x0D36, 0x0583, 0xEAF5, 0x185A, 0xF2C5, 0xF667, 0x17A8, 0xE7D9, 0x0702,
    0x0E28, 0xE65F, 0x136F, 0xFC5A, 0xEEF3, 0x1867, 0xED3D, 0x00CC, 0x1304, 0xE573, 0x0EBB, 0x02EE, 0xE846, 0x1900, 0xF480, 0xF7B9, 0x17CA, 0xE91D, 0x065D, 0x0A4B, 0xE764, 0x1454, 0xFBA6, 0xF203, 0x18DC,
    0xEC52, 0xFF18, 0x10FD, 0xE81D, 0x0D79, 0x042C, 0xEE1F, 0x148B, 0xF340, 0xF95A, 0x1222, 0xEA78, 0x09B4, 0x0998, 0xEACC, 0x1245, 0xF955, 0xF315, 0x1364, 0xEEC2, 0x03C9, 0x0D54, 0xEC15, 0x0EFA, 0xFD0A,
    0xF024, 0x1570, 0xF05C, 0xFE3E, 0x121F, 0xE9DA, 0x0A1A, 0x03F2, 0xECFE, 0x1437, 0xF6BD, 0xF924, 0x146C, 0xEA1A, 0x05AA, 0x0A5E, 0xE85A, 0x1257, 0xFE2D, 0xF083, 0x1710, 0xEF12, 0xFD2C, 0x100C, 0xE82F,
    0x0E1A, 0x04C5, 0xEC61, 0x164C, 0xF522, 0xF553, 0x154C, 0xEB67, 0x052E, 0x0CB0, 0xEA46, 0x106F, 0xFC5B, 0xF0D2, 0x1515, 0xEFD3, 0xFFC8, 0x115F, 0xE93D, 0x0B4D, 0x02F4, 0xEC23, 0x1365, 0xF749, 0xF976,
    0x13E5, 0xEC94, 0x05AA, 0x085A, 0xEA30, 0x11E8, 0xFC35, 0xF3AF, 0x1573, 0xEF93, 0xFF27, 0x0DA3, 0xEAF4, 0x0D7A, 0x01B2, 0xEFBE, 0x1506, 0xF2B4, 0xF9B4, 0x1228, 0xEA50, 0x0980, 0x0966, 0xEBB5, 0x128A,
    0xF811, 0xF434, 0x146E, 0xEC9B, 0x043F, 0x0E2B, 0xE9C6, 0x1073, 0xFE7A, 0xEDE2, 0x15E9, 0xF170, 0xFCAE, 0x13E9, 0xE8BC, 0x0A0C, 0x05C9, 0xE97F, 0x15C0, 0xF727, 0xF533, 0x183D, 0xEA6B, 0x032F, 0x0D54,
    0xE754, 0x1280, 0xFFE9, 0xEF87, 0x1825, 0xEF68, 0xFB4E, 0x130F, 0xE74D, 0x0C8E, 0x07AF, 0xEA53, 0x1697, 0xF608, 0xF445, 0x15B8, 0xEA05, 0x060B, 0x0DF7, 0xE7F8, 0x131C, 0xFC27, 0xEE55, 0x17DF, 0xEE5C,
    0xFEEB, 0x12CF, 0xE784, 0x0E4F, 0x027E, 0xE9EB, 0x17EF, 0xF31F, 0xF928, 0x177E, 0xE78F, 0x086C, 0x0939, 0xE624, 0x15DA, 0xF98D, 0xF308, 0x1A67, 0xE984, 0x0267, 0x105F, 0xE336, 0x1396, 0x008A, 0xEB9C,
    0x1BCD, 0xEE49, 0xFA10, 0x1600, 0xE425, 0x0E78, 0x08CF, 0xE647, 0x1AFC, 0xF46B, 0xF188, 0x1BA7, 0xE65F, 0x05FD, 0x1225, 0xE306, 0x15E2, 0xFCB7, 0xEAF3, 0x1CBE, 0xEB0D, 0xFDFF, 0x1837, 0xE248, 0x1019,
    0x05F2, 0xE4A3, 0x1BDF, 0xF2F2, 0xF5CE, 0x1BC5, 0xE39A, 0x092E, 0x0D25, 0xE0F8, 0x19C1, 0xF8FB, 0xEE60, 0x1F7F, 0xE739, 0x0058, 0x13DA, 0xE05C, 0x14FE, 0x01D7, 0xE88A, 0x1FA3, 0xEBC3, 0xF90C, 0x1A9D,
    0xDF05, 0x0F7C, 0x0B0D, 0xE284, 0x1DFC, 0xF326, 0xF12D, 0x1D46, 0xE238, 0x0872, 0x11A5, 0xDF27, 0x1ABA, 0xFA79, 0xE868, 0x21E7, 0xE7C2, 0xFF5A, 0x1A04, 0xDE6E, 0x139F, 0x034C, 0xE30D, 0x2175, 0xECB9,
    0xF6EF, 0x2085, 0xDE09, 0x0CB9, 0x0DD5, 0xDD90, 0x1D9D, 0xF791, 0xED7B, 0x227C, 0xE29F, 0x03D9, 0x15BC, 0xDA72, 0x1AD7, 0xFFCA, 0xE511, 0x2456, 0xE85E, 0xF8EB, 0x1C6C, 0xDC92, 0x11D5, 0x09B7, 0xE05F,
    0x2313, 0xEF2F, 0xF0AD, 0x22CF, 0xDD41, 0x0AB2, 0x139F, 0xDBBE, 0x1DE6, 0xF925, 0xE863, 0x23CC, 0xE365, 0x028C, 0x1A2F, 0xD970, 0x19CE, 0x01BE, 0xE07F, 0x2626, 0xE97B, 0xF7FB, 0x2195, 0xDAA7, 0x116C,
    0x0A3D, 0xDBEB, 0x23EF, 0xF087, 0xEF7C, 0x272E, 0xDCAF, 0x077E, 0x150E, 0xD769, 0x1EBF, 0xFC4B, 0xE6A0, 0x26B2, 0xE226, 0xFF04, 0x1CCB, 0xD62C, 0x19AF, 0x06E0, 0xDE07, 0x27CA, 0xEAE5, 0xF2A5, 0x2329,
    0xDA9A, 0x0F93, 0x0FDF, 0xDAB8, 0x23FA, 0xF27C, 0xE9FC, 0x283F, 0xDD1A, 0x05A6, 0x1AEE, 0xD6B6, 0x1D54, 0xFE57, 0xE1FC, 0x2797, 0xE3EF, 0xFD92, 0x20B2, 0xD58B, 0x178A, 0x086C, 0xD981, 0x28A9, 0xED8D,
    0xF170, 0x275D, 0xD92F, 0x0CEE, 0x10DE, 0xD6CA, 0x2485, 0xF58A, 0xE8F8, 0x2BA8, 0xDC63, 0x01F7, 0x1C47, 0xD44B, 0x1D53, 0x0208, 0xE12E, 0x29E7, 0xE33A, 0xF953, 0x2296, 0xD427, 0x173F, 0x0C9E, 0xD895,
    0x28F0, 0xEE44, 0xECB0, 0x2768, 0xDA1B, 0x0CA6, 0x1508, 0xD695, 0x240E, 0xF609, 0xE468, 0x2BF5, 0xDDC4, 0x019C, 0x202E, 0xD445, 0x1B00, 0x02EA, 0xDE0A, 0x2981, 0xE6BE, 0xF8B9, 0x255E, 0xD401, 0x1462,
    0x0DE5, 0xD60B, 0x286E, 0xF16E, 0xEC08, 0x2982, 0xDA0D, 0x08BB, 0x165A, 0xD489, 0x23C5, 0xFA43, 0xE333, 0x2D92, 0xDE82, 0xFCFD, 0x2122, 0xD340, 0x1A0B, 0x072F, 0xDCB9, 0x29FE, 0xE6B4, 0xF49C, 0x268B,
    0xD3DA, 0x13C0, 0x1246, 0xD4CC, 0x2763, 0xF21B, 0xE8FF, 0x29D9, 0xDA60, 0x0916, 0x196F, 0xD3C2, 0x2293, 0xFB1D, 0xE049, 0x2DB3, 0xE039, 0xFCC0, 0x2372, 0xD3B7, 0x1821, 0x07B9, 0xDAB5, 0x2A3D, 0xE90F,
    0xF4F0, 0x2804, 0xD439, 0x1066, 0x1140, 0xD528, 0x21FF, 0xFB87, 0xEF0F, 0x1AF5, 0xE100, 0x0777, 0x1248, 0xDDF9, 0x1DB3, 0x00C6, 0xE273, 0x279A, 0xE80B, 0xF40A, 0x1970, 0xE1A4, 0x120C, 0x038A, 0xEB06,
    0x2117, 0xE9FB, 0xF922, 0x1C5A, 0xDB2A, 0x0E14, 0x1037, 0xDA1B, 0x2068, 0xF788, 0xEA2B, 0x27F9, 0xE1F6, 0x0353, 0x176D, 0xD8FB, 0x1654, 0xFFC2, 0xE278, 0x27C5, 0xECFB, 0xF8F0, 0x219F, 0xDCBB, 0x0A0D,
    0x0B1B, 0xDEBC, 0x1DA8, 0xF4E2, 0xF33F, 0x2165, 0xE2FF, 0x05E9, 0x1329, 0xDF67, 0x1611, 0xFDDC, 0xEAD8, 0x1B39, 0xEA71, 0xFFEB, 0x14CC, 0xE4E2, 0x146F, 0x020B, 0xE879, 0x1BA3, 0xE88F, 0xFB48, 0x1781,
    0xE411, 0x1207, 0x0902, 0xE75F, 0x1BE1, 0xECD7, 0xF68D, 0x19E5, 0xE0BC, 0x0D0D, 0x0FD3, 0xE07A, 0x1AE1, 0xFA14, 0xEDBC, 0x1ECA, 0xE4E1, 0x046C, 0x1302, 0xDDC3, 0x15E6, 0x0211, 0xE584, 0x2468, 0xED6D,
    0xF7DD, 0x1C00, 0xDE9E, 0x090B, 0x0D5A, 0xE212, 0x1CC7, 0xF9B1, 0xF0E7, 0x1DD2, 0xE415, 0x0231, 0x1201, 0xDF96, 0x15BB, 0x0323, 0xE916, 0x1CC8, 0xEF11, 0xFB1B, 0x1537, 0xE568, 0x0D13, 0x06C5, 0xE648,
    0x18F9, 0xF264, 0xF6DF, 0x19CE, 0xE9C9, 0x07E9, 0x0CC9, 0xE598, 0x1174, 0xF772, 0xF213, 0x18DF, 0xEBB3, 0x06B2, 0x1037, 0xE572, 0x1216, 0xFDCC, 0xEBA4, 0x18E3, 0xED98, 0xFF9C, 0x1363, 0xE518, 0x1097,
    0x0467, 0xE841, 0x1B77, 0xF2C9, 0xF66B, 0x16AD, 0xE43C, 0x0873, 0x0C6D, 0xE5F8, 0x19DF, 0xFADF, 0xF05A, 0x1947, 0xE6F5, 0xFF92, 0x132D, 0xE319, 0x132F, 0x05EF, 0xEA24, 0x192B, 0xF04C, 0xF858, 0x152C,
    0xE676, 0x0B77, 0x09F2, 0xE64D, 0x177D, 0xF7CE, 0xF3A0, 0x17CB, 0xEC56, 0x04E5, 0x0C9B, 0xE626, 0x10FE, 0xFB6C, 0xF18A, 0x191B, 0xEF96, 0x0227, 0x101C, 0xE5BB, 0x0D00, 0xFFED, 0xEE7E, 0x168C, 0xF395,
    0xFEE4, 0x1119, 0xE91D, 0x0B07, 0x0459, 0xEAB3, 0x1695, 0xF646, 0xF6FE, 0x14C2, 0xE9B1, 0x0690, 0x0B07, 0xE9A2, 0x15A5, 0xFA14, 0xF06D, 0x16F8, 0xEB83, 0xFF53, 0x139E, 0xE79D, 0x0FE0, 0x0554, 0xEA70,
    0x14D4, 0xF23A, 0xF894, 0x1448, 0xE9C2, 0x0A9F, 0x0BF9, 0xE731, 0x1295, 0xFAF3, 0xF0E4, 0x159B, 0xF024, 0x0032, 0x0E09, 0xE8F6, 0x0D2E, 0x0135, 0xF031, 0x1568, 0xF505, 0xFB70, 0x0F82, 0xEA33, 0x0721,
    0x05B5, 0xEF4E, 0x1247, 0xFA8F, 0xF9C7, 0x0F81, 0xED6C, 0x0492, 0x0782, 0xEC67, 0x113F, 0xFD16, 0xF504, 0x1137, 0xF04D, 0x01DA, 0x0AFF, 0xEDEC, 0x0F20, 0xFDD8, 0xF0F0, 0x12E2, 0xF148, 0xFE0A, 0x11CD,
    0xECCA, 0x0BF1, 0x047C, 0xEBE8, 0x1040, 0xF570, 0xF807, 0x13BB, 0xEE47, 0x0863, 0x0A8E, 0xE8A2, 0x0EE6, 0xFD37, 0xF042, 0x139E, 0xF387, 0xFE50, 0x0EA4, 0xEB62, 0x0B0F, 0x0384, 0xEF2D, 0x1258, 0xF85F,
    0xF715, 0x0FAC, 0xEDC3, 0x03D1, 0x09D1, 0xF08C, 0x0E98, 0xFEB5, 0xF530, 0x0DB2, 0xF1AE, 0xFF21, 0x0AC3, 0xF09F, 0x0BF8, 0x028D, 0xF367, 0x0CC7, 0xF706, 0xFBD1, 0x0BCA, 0xF19D, 0x084F, 0x02A8, 0xF1E5,
    0x0D1A, 0xF8CE, 0xFA4E, 0x0EBA, 0xF2E2, 0x0521, 0x05EE, 0xEEF7, 0x0AF4, 0xFB98, 0xF770, 0x108B, 0xF51A, 0x00F0, 0x0AD7, 0xED11, 0x09A1, 0x0031, 0xF21B, 0x10DB, 0xF86A, 0xFBEB, 0x0E57, 0xEEF5, 0x05FF,
    0x065B, 0xEFC5, 0x0F31, 0xFC12, 0xF579, 0x0E15, 0xF2BF, 0x0006, 0x0B8D, 0xF199, 0x0BB0, 0x019F, 0xF1D8, 0x0C52, 0xF619, 0xFAD1, 0x0D51, 0xF2F2, 0x06EF, 0x06A2, 0xF164, 0x0A31, 0xFBC5, 0xF7E5, 0x0C33,
    0xF5AB, 0x01DD, 0x0816, 0xF17A, 0x0910, 0xFFAE, 0xF660, 0x0D71, 0xF822, 0xFDC3, 0x081A, 0xF199, 0x062C, 0x01E5, 0xF555, 0x0EAF, 0xFA92, 0xFB8B, 0x0A75, 0xF0F1, 0x031C, 0x04C0, 0xF314, 0x0CAC, 0xFD35,
    0xF8B0, 0x0C27, 0xF354, 0x014F, 0x081E, 0xF1B7, 0x0A73, 0x0037, 0xF387, 0x0CA4, 0xF6FE, 0xFC3D, 0x0C50, 0xF38E, 0x06B2, 0x0406, 0xF0FE, 0x0AA8, 0xFA61, 0xF878, 0x0EA8, 0xF619, 0x01AB, 0x0943, 0xF03E,
    0x0783, 0x0100, 0xF41B, 0x0D8E, 0xF9EE, 0xFCF2, 0x0A6C, 0xF26F, 0x04AA, 0x04A9, 0xF38C, 0x0BB1, 0xFD9F, 0xF83F, 0x0A70, 0xF549, 0x002C, 0x07AF, 0xF4A5, 0x09CF, 0x006B, 0xF66C, 0x093E, 0xF6B7, 0xFD79,
    0x08CF, 0xF5E6, 0x0790, 0x0374, 0xF552, 0x095C, 0xF941, 0xFB87, 0x09E4, 0xF57A, 0x04ED, 0x0501, 0xF257, 0x09D9, 0xFCA5, 0xF82E, 0x0D2C, 0xF645, 0x00F8, 0x0799, 0xF133, 0x07C1, 0x000D, 0xF588, 0x0E9D,
    0xF94F, 0xFCCD, 0x0AFE, 0xF0CF, 0x0437, 0x0526, 0xF257, 0x0D0C, 0xFDFF, 0xF798, 0x0C61, 0xF3EF, 0xFFC3, 0x095B, 0xF1B9, 0x09BD, 0x022C, 0xF35C, 0x0BE7, 0xF841, 0xFB75, 0x0BC8, 0xF461, 0x0596, 0x04F4,
    0xF1CE, 0x094A, 0xFBF8, 0xF85F, 0x0D13, 0xF6BE, 0x01FB, 0x0849, 0xF1A1, 0x06FB, 0xFF0D, 0xF5F3, 0x0C6C, 0xF8B8, 0xFF20, 0x0985, 0xF1C1, 0x06A7, 0x0278, 0xF405, 0x0CB5, 0xFB08, 0xFB57, 0x0A7A, 0xF220,
    0x03ED, 0x056B, 0xF2E1, 0x0D42, 0xFE1E, 0xF6D5, 0x0BFC, 0xF2CE, 0xFFE7, 0x0994, 0xF159, 0x0B23, 0x0173, 0xF340, 0x0D79, 0xF628, 0xFBF9, 0x0D7F, 0xF14C, 0x07B0, 0x0565, 0xEFF3, 0x0CC4, 0xFAC5, 0xF7CE,
    0x0FAA, 0xF3E6, 0x026E, 0x08CB, 0xEE14, 0x099C, 0xFF77, 0xF347, 0x10A4, 0xF823, 0xFCB7, 0x0CAC, 0xEF56, 0x05F3, 0x03A1, 0xF199, 0x0E99, 0xFBA0, 0xF909, 0x0DD0, 0xF1E1, 0x01F1, 0x0840, 0xF072, 0x0BDA,
    0xFF65, 0xF55E, 0x0D71, 0xF44C, 0xFEED, 0x0B11, 0xF172, 0x0ABE, 0x0216, 0xF20B, 0x0D12, 0xF626, 0xFB1B, 0x0D66, 0xF1F0, 0x08A2, 0x0575, 0xEFDA, 0x0DA4, 0xF911, 0xF7F1, 0x0FD8, 0xF1A8, 0x0465, 0x0938,
    0xED35, 0x0CEB, 0xFD57, 0xF3E9, 0x12C2, 0xF428, 0xFF24, 0x0C59, 0xEBD9, 0x09F7, 0x0334, 0xF014, 0x12FF, 0xF8B5, 0xF910, 0x1023, 0xED20, 0x0444, 0x08DF, 0xED9B, 0x10DD, 0xFDDE, 0xF3B2, 0x111F, 0xF13E,
    0xFED8, 0x0D40, 0xED5A, 0x0BDE, 0x02F8, 0xEFFC, 0x1054, 0xF5DA, 0xFB13, 0x0FB3, 0xF03B, 0x07D2, 0x062A, 0xEE15, 0x0E45, 0xF92F, 0xF76A, 0x114F, 0xF25E, 0x0426, 0x08FE, 0xED65, 0x0CD8, 0xFCEA, 0xF35B,
    0x1218, 0xF333, 0x0001, 0x0CDE, 0xEBDC, 0x0A5C, 0x01CF, 0xEFE7, 0x13A0, 0xF68F, 0xFABD, 0x0FD3, 0xEB71, 0x076A, 0x0778, 0xED51, 0x1343, 0xFAC4, 0xF461, 0x1226, 0xED2B, 0x01D8, 0x0C52, 0xEC21, 0x106A,
    0x002F, 0xEFF5, 0x138D, 0xF183, 0xFBD8, 0x10E0, 0xEBC4, 0x0B2E, 0x0635, 0xEC4E, 0x127A, 0xF70D, 0xF692, 0x1403, 0xEE06, 0x0545, 0x09F1, 0xE9FC, 0x0FBB, 0xFCD9, 0xF2BE, 0x14D1, 0xF250, 0x0030, 0x0CBE,
    0xEA08, 0x0B4E, 0x0111, 0xEFA7, 0x1428, 0xF63D, 0xFB78, 0x0FDD, 0xEB67, 0x0802, 0x0651, 0xED9C, 0x12EA, 0xF8EF, 0xF619, 0x1179, 0xECDE, 0x04C3, 0x0AD2, 0xEBFA, 0x11A9, 0xFD34, 0xF119, 0x13F7, 0xEF44,
    0xFF51, 0x0FBF, 0xEB0C, 0x0F5C, 0x0280, 0xEC92, 0x14B0, 0xF267, 0xF903, 0x1408, 0xEADB, 0x0A5F, 0x0875, 0xE8C4, 0x1354, 0xF8B5, 0xF3A6, 0x16D1, 0xED15, 0x0390, 0x0D96, 0xE6FD, 0x1020, 0xFFB1, 0xEF06,
    0x174B, 0xF219, 0xFC51, 0x10D0, 0xE7C3, 0x0B1E, 0x0517, 0xEC5D, 0x15CC, 0xF78B, 0xF71F, 0x12BD, 0xEAB7, 0x0502, 0x0A35, 0xEB55, 0x12CE, 0xFC15, 0xF299, 0x1409, 0xEE60, 0x0126, 0x0E3F, 0xEA92, 0x0FEE,
    0xFFB6, 0xEE1E, 0x1466, 0xF1AB, 0xFC83, 0x11C2, 0xEB36, 0x0C20, 0x0496, 0xEA8C, 0x142F, 0xF59B, 0xF6F7, 0x15BF, 0xEC74, 0x06FF, 0x0A8C, 0xE824, 0x12C5, 0xFB57, 0xF1AE, 0x1816, 0xEE20, 0x00CD, 0x0F97,
    0xE68E, 0x0F96, 0x0223, 0xECEF, 0x1863, 0xF2EC, 0xF8E5, 0x12F6, 0xE817, 0x0960, 0x087C, 0xEA85, 0x173E, 0xF914, 0xF2EA, 0x154B, 0xEABC, 0x0314, 0x0DAE, 0xE9D2, 0x12A4, 0xFE7B, 0xEF89, 0x15FB, 0xEF1D,
    0xFDEB, 0x1172, 0xEA29, 0x0D79, 0x0322, 0xEBAC, 0x1479, 0xF431, 0xF926, 0x146B, 0xEBEF, 0x08B0, 0x0759, 0xE8F5, 0x12E0, 0xF830, 0xF4D1, 0x1723, 0xEE0F, 0x03A7, 0x0BA5, 0xE846, 0x0FCD, 0xFD91, 0xF013,
    0x1792, 0xF0E1, 0xFDD4, 0x1042, 0xE7B6, 0x0CEC, 0x03E5, 0xEC01, 0x1792, 0xF4AC, 0xF756, 0x13F5, 0xE852, 0x0874, 0x0A0B, 0xEA1C, 0x15BE, 0xF987, 0xF128, 0x16CA, 0xEB74, 0x00BF, 0x1053, 0xE8BE, 0x1156,
    0x005D, 0xECB7, 0x16C2, 0xF073, 0xFB8C, 0x14B3, 0xE989, 0x0B79, 0x06A7, 0xE94B, 0x143F, 0xF6F7, 0xF5EB, 0x15FC, 0xEC2C, 0x056B, 0x0A20, 0xE7CF, 0x11F0, 0xFC70, 0xF27E, 0x178E, 0xEF58, 0xFFF5, 0x0DC6,
    0xE85C, 0x0DF4, 0x0082, 0xEF54, 0x16A3, 0xF2B9, 0xFB58, 0x117D, 0xE8FC, 0x0A4C, 0x06BA, 0xEC97, 0x1539, 0xF6DE, 0xF583, 0x1417, 0xEBA0, 0x0608, 0x0BBE, 0xEA75, 0x1366, 0xFBA6, 0xEF89, 0x15AE, 0xEE6E,
    0xFFEF, 0x11DC, 0xE964, 0x0E74, 0x01B5, 0xEB8B, 0x1606, 0xF227, 0xF999, 0x15D9, 0xEA7A, 0x08EF, 0x084D, 0xE8E8, 0x1351, 0xF98C, 0xF467, 0x16E0, 0xED34, 0x02E4, 0x0C69, 0xE841, 0x109A, 0xFF5F, 0xF0A7,
    0x1766, 0xF147, 0xFC21, 0x1003, 0xE99D, 0x0B90, 0x0462, 0xEF29, 0x15A8, 0xF506, 0xF81D, 0x128C, 0xEB12, 0x074F, 0x09DC, 0xEC74, 0x12F9, 0xF9F0, 0xF39D, 0x13ED, 0xEDB8, 0x0359, 0x0DDB, 0xEB8F, 0x105E,
    0xFE39, 0xEEC8, 0x14F1, 0xF1BE, 0xFDF8, 0x1219, 0xEBF0, 0x0B30, 0x02A8, 0xEC39, 0x1358, 0xF544, 0xF8DB, 0x157C, 0xEC88, 0x068B, 0x0941, 0xE9BE, 0x1186, 0xFC2D, 0xF350, 0x1580, 0xEFB0, 0x0056, 0x0D45,
    0xE91D, 0x0EC0, 0x0249, 0xEF80, 0x15FC, 0xF389, 0xF8FF, 0x10D5, 0xEA74, 0x095A, 0x074E, 0xEDDD, 0x13E0, 0xF76C, 0xF567, 0x1257, 0xECE8, 0x0439, 0x0CA3, 0xEC95, 0x1038, 0xFD25, 0xF1B4, 0x12C4, 0xF093,
    0x0036, 0x0F15, 0xEC68, 0x0BB0, 0x010D, 0xEE73, 0x1276, 0xF57A, 0xFBBD, 0x11D2, 0xEDEB, 0x0798, 0x0476, 0xEC83, 0x112C, 0xF89F, 0xF7A8, 0x1449, 0xEEEE, 0x02ED, 0x09D3, 0xEAD3, 0x0E8F, 0xFE89, 0xF3D2,
    0x140F, 0xF1A7, 0xFE12, 0x0D91, 0xEB12, 0x0B3E, 0x042D, 0xEF39, 0x1373, 0xF5A2, 0xF779, 0x108B, 0xED9A, 0x06F1, 0x093F, 0xEE9E, 0x108A, 0xFA25, 0xF3A7, 0x11F1, 0xEFCA, 0x014E, 0x0DEB, 0xEDDB, 0x0C89,
    0x0020, 0xF083, 0x10DD, 0xF434, 0xFD5B, 0x0F7D, 0xEE1B, 0x087B, 0x03C4, 0xEE6C, 0x1019, 0xF95B, 0xF910, 0x113F, 0xF085, 0x032D, 0x0712, 0xEE28, 0x0EB9, 0xFC92, 0xF66A, 0x1272, 0xF1B7, 0xFF52, 0x0AB3,
    0xED8B, 0x0B02, 0x01BD, 0xF382, 0x1136, 0xF4AD, 0xFBF1, 0x0D3A, 0xEDDD, 0x083F, 0x063D, 0xF0D9, 0x1016, 0xF93B, 0xF626, 0x0F5D, 0xF155, 0x03B8, 0x0A08, 0xEF72, 0x0CC0, 0xFCCC, 0xF2C4, 0x105F, 0xF3B0,
    0xFF14, 0x0E97, 0xEFBA, 0x084A, 0x01A4, 0xF091, 0x0ECF, 0xF7B3, 0xFBD0, 0x0FA5, 0xF06E, 0x0489, 0x062B, 0xEEB0, 0x0CF1, 0xFD90, 0xF73B, 0x0FBD, 0xF2F4, 0xFFAF, 0x08B6, 0xEFAC, 0x0B19, 0x00BA, 0xF529,
    0x0FB2, 0xF572, 0xFB3E, 0x0B78, 0xF0E2, 0x06CE, 0x04D6, 0xF351, 0x0D98, 0xF88C, 0xF879, 0x0CE5, 0xF14D, 0x0417, 0x086F, 0xF123, 0x0C0A, 0xFCD7, 0xF55C, 0x0D92, 0xF4B9, 0x0138, 0x0AF6, 0xF13C, 0x08CF,
    0xFFE8, 0xF2FE, 0x0ECF, 0xF7C1, 0xFC90, 0x0DEF, 0xF1EC, 0x03FF, 0x0438, 0xF197, 0x0C2A, 0xFBF8, 0xF9A0, 0x0EAD, 0xF2C4, 0x00A7, 0x07DE, 0xF0C1, 0x09BB, 0x00C2, 0xF5E3, 0x0DAD, 0xF6D8, 0xFCF2, 0x09CF,
    0xF1BC, 0x076C, 0x0406, 0xF3BE, 0x0C75, 0xF8FB, 0xF829, 0x0C4B, 0xF3D0, 0x02EE, 0x0799, 0xF3DC, 0x097A, 0xFC37, 0xF6A7, 0x0C0D, 0xF55E, 0x0035, 0x0A6B, 0xF358, 0x06F6, 0x003F, 0xF43B, 0x0BDF, 0xF911,
    0xFD42, 0x0B11, 0xF345, 0x050D, 0x02F9, 0xF2E5, 0x0B6E, 0xFC8F, 0xFA18, 0x0CE3, 0xF4EC, 0x0050, 0x0577, 0xF30C, 0x0901, 0xFF74, 0xF84C, 0x0CA3, 0xF68B, 0xFD46, 0x0972, 0xF233, 0x0624, 0x041C, 0xF553,
    0x0B02, 0xF995, 0xF9A8, 0x0A33, 0xF467, 0x0419, 0x073E, 0xF3AC, 0x092D, 0xFD35, 0xF605, 0x0C04, 0xF7A6, 0xFFA5, 0x09B2, 0xF499, 0x05B0, 0xFFD6, 0xF594, 0x0AD9, 0xF995, 0xFCD1, 0x0BA6, 0xF448, 0x02B1,
    0x0403, 0xF3FC, 0x0901, 0xFDDB, 0xFA8A, 0x0B54, 0xF5E4, 0xFFCE, 0x06AA, 0xF364, 0x080C, 0x0118, 0xF798, 0x0B1A, 0xF892, 0xFBC5, 0x0802, 0xF469, 0x05AF, 0x0425, 0xF671, 0x0AB8, 0xF9E5, 0xF9BB, 0x0A66,
    0xF5B7, 0x0291, 0x0756, 0xF5AC, 0x07B5, 0xFDA6, 0xF7DD, 0x0A1C, 0xF7DF, 0x0064, 0x0939, 0xF472, 0x05F4, 0x014C, 0xF4BD, 0x0A8D, 0xFB5B, 0xFC6D, 0x0B29, 0xF5C1, 0x027B, 0x03EF, 0xF3CE, 0x09B0, 0xFDEC,
    0xF95F, 0x0C13, 0xF66E, 0xFE1B, 0x0720, 0xF447, 0x0640, 0x0224, 0xF77B, 0x0A4F, 0xF94C, 0xFC18, 0x0916, 0xF479, 0x0485, 0x0595, 0xF537, 0x08AE, 0xFC27, 0xF8B3, 0x09E4, 0xF71B, 0x01E2, 0x0753, 0xF4EC,
    0x076D, 0xFE4A, 0xF677, 0x0A86, 0xF84F, 0xFE95, 0x0A3E, 0xF542, 0x03F3, 0x01E0, 0xF5A0, 0x097F, 0xFAF6, 0xFC2B, 0x0AE7, 0xF496, 0x01A2, 0x04B5, 0xF35F, 0x08BB, 0xFF68, 0xF904, 0x0B56, 0xF6DB, 0xFE09,
    0x072A, 0xF388, 0x0709, 0x01D0, 0xF6A5, 0x0BDE, 0xF922, 0xFA41, 0x09E7, 0xF4D6, 0x0337, 0x05DA, 0xF5D5, 0x0974, 0xFC02, 0xF826, 0x0B32, 0xF601, 0x011B, 0x0986, 0xF37A, 0x0729, 0x0016, 0xF53F, 0x0AC7,
    0xF9AA, 0xFDDA, 0x0A62, 0xF43D, 0x041B, 0x025D, 0xF31D, 0x0A6C, 0xFC72, 0xF9F0, 0x0C51, 0xF635, 0xFFF3, 0x05FA, 0xF359, 0x0911, 0xFEDC, 0xF888, 0x0CFE, 0xF5E7, 0xFDB6, 0x0912, 0xF2B8, 0x06CB, 0x03BB,
    0xF5AD, 0x0B51, 0xF94E, 0xFA72, 0x0A2A, 0xF3BC, 0x0481, 0x06CD, 0xF3B1, 0x0B06, 0xFC16, 0xF641, 0x0BCB, 0xF5DD, 0x00E6, 0x0924, 0xF362, 0x0821, 0xFF14, 0xF495, 0x0CB5, 0xF78F, 0xFDBD, 0x0C92, 0xF298,
    0x047D, 0x03C5, 0xF2BD, 0x0AE5, 0xFC0E, 0xFA7B, 0x0CE5, 0xF3BF, 0x01A4, 0x06AF, 0xF133, 0x09E7, 0xFFDD, 0xF6C8, 0x0D54, 0xF6CB, 0xFD33, 0x095D, 0xF236, 0x072B, 0x02D9, 0xF4DA, 0x0D7B, 0xF853, 0xF976,
    0x0C45, 0xF264, 0x0409, 0x0769, 0xF30C, 0x0AF1, 0xFC36, 0xF711, 0x0CBF, 0xF459, 0x01C2, 0x0A46, 0xF12D, 0x0929, 0xFFA6, 0xF3B2, 0x0D86, 0xF798, 0xFD70, 0x0C46, 0xF229, 0x068B, 0x02B0, 0xF1E4, 0x0D67,
    0xF9F7, 0xFA16, 0x0EFB, 0xF246, 0x01AD, 0x0702, 0xF05A, 0x0B20, 0xFE9C, 0xF7B0, 0x0EF9, 0xF346, 0xFEE3, 0x0A80, 0xEF28, 0x097B, 0x02E5, 0xF375, 0x0E92, 0xF74D, 0xFA0B, 0x0C19, 0xF14D, 0x061E, 0x0628,
    0xF1D1, 0x0D8A, 0xFA27, 0xF5E2, 0x0EC1, 0xF357, 0x0178, 0x0AA4, 0xF0AF, 0x0A50, 0xFE6A, 0xF385, 0x0E97, 0xF55F, 0xFEDE, 0x0D5F, 0xEFC1, 0x070A, 0x0328, 0xF06B, 0x0E5D, 0xFA00, 0xFA52, 0x0EAC, 0xF0DD,
    0x03FA, 0x0614, 0xEF20, 0x0DF3, 0xFCBD, 0xF662, 0x10DC, 0xF24C, 0xFF48, 0x0A82, 0xEF5A, 0x0B11, 0x0160, 0xF435, 0x1095, 0xF4C0, 0xFBAC, 0x0D6E, 0xEE88, 0x0848, 0x05CC, 0xF105, 0x0EEB, 0xF8BF, 0xF7D5,
    0x0EEC, 0xF125, 0x0498, 0x0944, 0xEEC3, 0x0D3C, 0xFC3E, 0xF38D, 0x109E, 0xF36F, 0xFFB4, 0x0D07, 0xEF1A, 0x0972, 0x00B7, 0xF0C7, 0x1042, 0xF68F, 0xFC54, 0x1024, 0xEE9B, 0x05EC, 0x0640, 0xEE5A, 0x0F18,
    0xFC0C, 0xF873, 0x10D3, 0xF0BD, 0x020F, 0x0917, 0xED1F, 0x0D2A, 0xFF7D, 0xF3A6, 0x120B, 0xF329, 0xFCBF, 0x0C87, 0xEDE6, 0x0A07, 0x041F, 0xF13D, 0x1117, 0xF607, 0xF940, 0x104C, 0xEED5, 0x0652, 0x08E5,
    0xEEC5, 0x0E51, 0xFB12, 0xF4F8, 0x1087, 0xF09E, 0x02F5, 0x0C01, 0xECD8, 0x0CB9, 0xFED9, 0xF0C4, 0x1253, 0xF4B1, 0xFCFB, 0x0FA8, 0xED89, 0x07F6, 0x030D, 0xEEE8, 0x1163, 0xF7E9, 0xF981, 0x11F0, 0xEDAC,
    0x039A, 0x088E, 0xECF8, 0x0EEB, 0xFE22, 0xF5CC, 0x120C, 0xF06F, 0x0026, 0x0C08, 0xEBD5, 0x0D98, 0x021F, 0xF137, 0x121C, 0xF4B7, 0xFA8D, 0x0F09, 0xEE53, 0x08C7, 0x06B8, 0xEF4B, 0x10DD, 0xF76B, 0xF6A3,
    0x11AD, 0xEE9C, 0x0453, 0x0BBB, 0xED57, 0x0DCA, 0xFCED, 0xF2D6, 0x11FC, 0xF20C, 0x010E, 0x0E0A, 0xEB8B, 0x0B41, 0x0162, 0xEF0E, 0x12C9, 0xF69A, 0xFB99, 0x1093, 0xED5D, 0x073C, 0x0547, 0xED0C, 0x121B,
    0xFA2E, 0xF746, 0x1365, 0xEDD7, 0x020C, 0x0ABB, 0xEC75, 0x0E8A, 0xFF9C, 0xF379, 0x1226, 0xF140, 0xFD91, 0x0E40, 0xEBBF, 0x0C36, 0x04CE, 0xEF11, 0x11DC, 0xF57E, 0xF8CA, 0x1046, 0xEDE8, 0x07BE, 0x0840,
    0xED49, 0x1034, 0xF8A7, 0xF474, 0x12CD, 0xF023, 0x032A, 0x0C7D, 0xEC4B, 0x0C83, 0xFE75, 0xF1A7, 0x12E3, 0xF387, 0xFE73, 0x0F23, 0xEB19, 0x0923, 0x03D0, 0xEDC4, 0x123A, 0xF939, 0xF97B, 0x1127, 0xED38,
    0x04D4, 0x07B2, 0xEC8A, 0x114B, 0xFB73, 0xF4EB, 0x12BC, 0xEEF0, 0x007A, 0x0C6D, 0xECE4, 0x0D16, 0x0188, 0xF1D4, 0x11C5, 0xF2A6, 0xFB60, 0x100D, 0xEC6C, 0x0AA3, 0x06B7, 0xEDB7, 0x114D, 0xF71D, 0xF74C,
    0x10F1, 0xEF54, 0x063A, 0x09A0, 0xEBFC, 0x0EFB, 0xFC09, 0xF2EE, 0x138D, 0xF1CC, 0x0079, 0x0DDC, 0xEC23, 0x0AAC, 0x00A4, 0xF0A0, 0x12CE, 0xF53D, 0xFD05, 0x1063, 0xEB67, 0x0729, 0x0567, 0xEDCB, 0x1129,
    0xFAE1, 0xF763, 0x10EC, 0xEF19, 0x02C5, 0x0944, 0xEC8F, 0x0FBA, 0xFE8B, 0xF322, 0x1244, 0xF188, 0xFE2B, 0x0D1D, 0xED31, 0x0BE0, 0x02F0, 0xF05E, 0x1111, 0xF41B, 0xFA5E, 0x1049, 0xEDD4, 0x088E, 0x0837,
    0xED8E, 0x0EF0, 0xF9AF, 0xF5A2, 0x1181, 0xF0FC, 0x03C8, 0x0AD7, 0xEC8A, 0x0D25, 0xFDF0, 0xF1B7, 0x1309, 0xF430, 0xFE11, 0x0EAD, 0xEC95, 0x0912, 0x02D0, 0xF050, 0x1275, 0xF79B, 0xFA76, 0x1053, 0xED14,
    0x04F3, 0x080F, 0xEE34, 0x0FE3, 0xFCBB, 0xF5DE, 0x0FE8, 0xF006, 0x018C, 0x0A6B, 0xED84, 0x0E2B, 0x0080, 0xF1C9, 0x1067, 0xF3CD, 0xFC48, 0x0DC7, 0xEF9B, 0x09BE, 0x0485, 0xEFDB, 0x0F64, 0xF734, 0xF8D7,
    0x1066, 0xEFF6, 0x0556, 0x092E, 0xED77, 0x0C85, 0xFC8A, 0xF471, 0x109E, 0xF34D, 0x01F8, 0x0AF5, 0xECDC, 0x0B50, 0x008F, 0xF161, 0x1178, 0xF792, 0xFC1C, 0x0DD9, 0xEE4C, 0x06AD, 0x049D, 0xF067, 0x10FB,
    0xF9C0, 0xF84B, 0x0FE2, 0xEF22, 0x02EB, 0x097A, 0xEEEB, 0x0D2B, 0xFED8, 0xF4AD, 0x0F39, 0xF25C, 0xFEFA, 0x0C48, 0xEF07, 0x0B96, 0x026A, 0xF12B, 0x0EF2, 0xF636, 0xFAB9, 0x0E13, 0xF1AF, 0x0730, 0x0562,
    0xEFE2, 0x0D5F, 0xF9C6, 0xF7F8, 0x1052, 0xF357, 0x02D3, 0x095E, 0xEF0C, 0x0A0D, 0xFE72, 0xF49D, 0x0FC5, 0xF614, 0xFF73, 0x0B3F, 0xEE1F, 0x0810, 0x0303, 0xF1E5, 0x0F5E, 0xF9D3, 0xFA27, 0x0D1C, 0xF104,
    0x041E, 0x05BC, 0xF11F, 0x0E1A, 0xFC15, 0xF715, 0x0E12, 0xF225, 0x007B, 0x0A36, 0xF0FB, 0x0AE5, 0x00D6, 0xF3EA, 0x0D45, 0xF567, 0xFD50, 0x0C17, 0xF1BA, 0x0879, 0x04B9, 0xF12B, 0x0CA7, 0xF9B6, 0xF900,
    0x0D44, 0xF45D, 0x0496, 0x0663, 0xF086, 0x0AC1, 0xFCCD, 0xF664, 0x0EFD, 0xF5AC, 0xFFD0, 0x096D, 0xF06C, 0x07BD, 0x0109, 0xF4A2, 0x0E18, 0xF8DA, 0xFD03, 0x0B17, 0xF0F8, 0x0542, 0x04E6, 0xF2DE, 0x0CE9,
    0xFCC3, 0xF883, 0x0B7E, 0xF3A6, 0x01A6, 0x075B, 0xF2F1, 0x0AF6, 0xFF43, 0xF5A6, 0x0C28, 0xF5D2, 0xFE0B, 0x0A77, 0xF3D2, 0x075B, 0x0254, 0xF3FB, 0x0A98, 0xF92C, 0xFBA8, 0x0C19, 0xF3E3, 0x04B5, 0x0585,
    0xF223, 0x0987, 0xFC7A, 0xF85A, 0x0CA1, 0xF708, 0x00D5, 0x071D, 0xF21E, 0x0791, 0xFF83, 0xF60A, 0x0D64, 0xF979, 0xFCD7, 0x09F0, 0xF2F8, 0x0437, 0x0346, 0xF59B, 0x0BAB, 0xFB24, 0xFAC6, 0x0A88, 0xF43E,
    0x0237, 0x067F, 0xF42B, 0x0987, 0xFF2E, 0xF75C, 0x0A01, 0xF6E2, 0xFF28, 0x07ED, 0xF4CE, 0x0822, 0x012C, 0xF53A, 0x0A18, 0xF91C, 0xFBB1, 0x0A8B, 0xF692, 0x0418, 0x03FE, 0xF4C5, 0x0874, 0xFB6A, 0xFA0D,
    0x0AF9, 0xF74D, 0x0136, 0x062E, 0xF3C9, 0x067D, 0x003D, 0xF79A, 0x0A9E, 0xFA3C, 0xFE69, 0x0774, 0xF45E, 0x0461, 0x0277, 0xF5D0, 0x0A87, 0xFC83, 0xF9F2, 0x08AE, 0xF5F9, 0x00CF, 0x050D, 0xF692, 0x0861,
    0xFEF0, 0xF899, 0x0950, 0xF710, 0xFEBA, 0x082E, 0xF633, 0x0645, 0x01CA, 0xF6E1, 0x07D1, 0xFA66, 0xFCDE, 0x0866, 0xF6EC, 0x0446, 0x0371, 0xF49E, 0x0784, 0xFCCA, 0xF97E, 0x0A0E, 0xF9AB, 0x0035, 0x0577,
    0xF56E, 0x056E, 0xFFA8, 0xF83D, 0x09EC, 0xFA72, 0xFDCA, 0x0736, 0xF582, 0x02F6, 0x02DD, 0xF721, 0x087C, 0xFD02, 0xFAEB, 0x07AA, 0xF6A8, 0x019A, 0x0518, 0xF66A, 0x07EE, 0x002A, 0xF834, 0x0812, 0xF940,
    0xFE02, 0x06BF, 0xF7BA, 0x054E, 0x014D, 0xF76B, 0x07DC, 0xFB1E, 0xFB9C, 0x08C9, 0xF8A0, 0x0246, 0x03D8, 0xF66C, 0x0623, 0xFE39, 0xFA8B, 0x08AF, 0xFA1C, 0x0084, 0x05D2, 0xF53B, 0x0423, 0x00FD, 0xF835,
    0x094B, 0xFCDC, 0xFD11, 0x0695, 0xF696, 0x0207, 0x02DF, 0xF7D2, 0x0852, 0xFD75, 0xF9F3, 0x07D0, 0xF813, 0xFF8D, 0x0584, 0xF7E0, 0x0634, 0x007C, 0xF8B1, 0x0770, 0xF9F7, 0xFDAB, 0x0718, 0xF7B1, 0x04D4,
    0x0319, 0xF6E4, 0x0667, 0xFCC2, 0xFB67, 0x07D1, 0xF965, 0x022F, 0x0479, 0xF5E6, 0x05B8, 0xFE55, 0xF93F, 0x09CB, 0xFADD, 0xFE93, 0x0670, 0xF683, 0x0372, 0x01A0, 0xF7EB, 0x08CE, 0xFC5E, 0xFC6B, 0x0783,
    0xF675, 0x0194, 0x03FE, 0xF704, 0x0777, 0xFF8E, 0xF9AB, 0x0763, 0xF87B, 0xFF6C, 0x05F1, 0xF72B, 0x06B8, 0x00FC, 0xF700, 0x07DA, 0xFA69, 0xFC16, 0x087E, 0xF7E4, 0x0381, 0x03CB, 0xF686, 0x06E2, 0xFCE2,
    0xFAEC, 0x0923, 0xF898, 0x0110, 0x058C, 0xF4F4, 0x0540, 0x0008, 0xF84F, 0x0923, 0xFB63, 0xFE8E, 0x06E1, 0xF576, 0x0393, 0x0269, 0xF6FA, 0x093D, 0xFD00, 0xFAF3, 0x0834, 0xF6CD, 0x00E4, 0x04A2, 0xF717,
    0x0867, 0xFF30, 0xF888, 0x0894, 0xF833, 0xFE16, 0x076F, 0xF65D, 0x05CC, 0x021F, 0xF660, 0x0854, 0xFA3A, 0xFB9A, 0x08E6, 0xF70F, 0x03E6, 0x0422, 0xF468, 0x07D6, 0xFD30, 0xF8B3, 0x0A98, 0xF91D, 0x0060,
    0x0616, 0xF438, 0x0585, 0xFFE3, 0xF77A, 0x0AB8, 0xFA00, 0xFD27, 0x0858, 0xF406, 0x02F5, 0x0339, 0xF5FB, 0x0A2B, 0xFD10, 0xFA95, 0x0913, 0xF558, 0x011C, 0x0620, 0xF558, 0x0946, 0x0039, 0xF6D4, 0x098E,
    0xF74C, 0xFE61, 0x0804, 0xF436, 0x074D, 0x020B, 0xF632, 0x097F, 0xF86A, 0xFBFA, 0x0AD1, 0xF65A, 0x02E4, 0x0536, 0xF4D4, 0x083A, 0xFCF7, 0xF8DD, 0x0BEE, 0xF729, 0x0117, 0x072B, 0xF32D, 0x06D0, 0xFFDF,
    0xF65E, 0x0C57, 0xF9D7, 0xFD32, 0x0998, 0xF2F1, 0x0513, 0x02D5, 0xF4F9, 0x0BF6, 0xFBD2, 0xF9DF, 0x0A11, 0xF4C9, 0x0138, 0x065E, 0xF412, 0x0A00, 0xFEE2, 0xF6CF, 0x0B73, 0xF58F, 0xFF40, 0x08D9, 0xF36B,
    0x0866, 0x01F9, 0xF455, 0x0AF6, 0xF917, 0xFB90, 0x0B82, 0xF46A, 0x0556, 0x048F, 0xF2D3, 0x0A32, 0xFBCD, 0xF82F, 0x0D4D, 0xF610, 0x01BC, 0x084D, 0xF0B6, 0x0919, 0xFE89, 0xF698, 0x0DE3, 0xF79E, 0xFE6A,
    0x0941, 0xF1E0, 0x0598, 0x0351, 0xF365, 0x0D46, 0xFAB8, 0xFA25, 0x0B71, 0xF209, 0x03F8, 0x0546, 0xF33E, 0x0C69, 0xFDC3, 0xF6BA, 0x0C91, 0xF4F2, 0xFF4F, 0x09B2, 0xF214, 0x0A0A, 0x00C9, 0xF466, 0x0C7C,
    0xF685, 0xFD0D, 0x0BC0, 0xF2C5, 0x0754, 0x0465, 0xF0E8, 0x0BBA, 0xFB0C, 0xF9E6, 0x0D90, 0xF3DB, 0x048E, 0x077B, 0xF014, 0x0AB3, 0xFDC9, 0xF69F, 0x0E66, 0xF59A, 0xFF4F, 0x0A36, 0xF009, 0x06FB, 0x017E,
    0xF3B5, 0x0EB6, 0xF83D, 0xFB9D, 0x0CE4, 0xF0D0, 0x04F1, 0x061F, 0xF1E1, 0x0E55, 0xFC1D, 0xF7E4, 0x0D34, 0xF20F, 0x01E2, 0x0840, 0xF20C, 0x0BC7, 0xFF43, 0xF3B1, 0x0DB3, 0xF516, 0xFD77, 0x0C2A, 0xF150,
    0x091C, 0x02B4, 0xF195, 0x0DBA, 0xF837, 0xFAB7, 0x0E98, 0xF268, 0x04D0, 0x069C, 0xF033, 0x0C2B, 0xFBCF, 0xF73E, 0x0FF6, 0xF463, 0x01A5, 0x08EA, 0xEED3, 0x0A25, 0x0044, 0xF38A, 0x1053, 0xF688, 0xFCF5,
    0x0B7A, 0xEF53, 0x07DA, 0x03C4, 0xF2B0, 0x0FCA, 0xF946, 0xF95F, 0x0DB3, 0xEFFC, 0x0428, 0x0813, 0xF12A, 0x0CE1, 0xFD6A, 0xF4D3, 0x0EA4, 0xF2F8, 0xFF7F, 0x0BC9, 0xF006, 0x0BAE, 0x00C7, 0xF191, 0x0EBF,
    0xF5C5, 0xFC8E, 0x0DF6, 0xF136, 0x072E, 0x0424, 0xEF86, 0x0DCB, 0xF9AC, 0xF7F9, 0x10C3, 0xF1CA, 0x03C9, 0x07B9, 0xEE5D, 0x0BD3, 0xFDDF, 0xF5BD, 0x1059, 0xF45C, 0xFE75, 0x0B27, 0xEE19, 0x09D7, 0x01AB,
    0xF2B5, 0x10DD, 0xF6FD, 0xFAA3, 0x0CD7, 0xEF11, 0x05EF, 0x0616, 0xF0F2, 0x0F66, 0xFAD1, 0xF6B3, 0x0F2C, 0xF125, 0x0235, 0x09E7, 0xF017, 0x0CF2, 0xFEA9, 0xF391, 0x0F2C, 0xF383, 0xFE9E, 0x0D85, 0xEF10,
    0x09F3, 0x0267, 0xF06E, 0x0F3B, 0xF74D, 0xFA59, 0x0F54, 0xF16E, 0x0555, 0x0624, 0xEE98, 0x0DE9, 0xFB9C, 0xF699, 0x1152, 0xF278, 0x0148, 0x09BC, 0xEE04, 0x0B79, 0xFF9D, 0xF439, 0x119E, 0xF476, 0xFD09,
    0x0C1F, 0xEDBE, 0x0884, 0x0396, 0xF191, 0x107E, 0xF8C9, 0xF895, 0x0E8C, 0xEFE8, 0x04B1, 0x0811, 0xF06C, 0x0E88, 0xFBDD, 0xF518, 0x0FE6, 0xF26A, 0x0072, 0x0C01, 0xEFD1, 0x0BAF, 0x0013, 0xF1E2, 0x0FAD,
    0xF533, 0xFD73, 0x0E56, 0xEF92, 0x086E, 0x03C6, 0xEF84, 0x0E64, 0xF960, 0xF98D, 0x0FDA, 0xF19E, 0x0366, 0x0784, 0xEE52, 0x0CE7, 0xFD13, 0xF584, 0x1101, 0xF33F, 0xFF3F, 0x0AC2, 0xEEA3, 0x09D2, 0x01FC,
    0xF375, 0x1053, 0xF6A4, 0xFB54, 0x0D16, 0xEF26, 0x0704, 0x059F, 0xF0C2, 0x0F67, 0xF9B1, 0xF75E, 0x0F0E, 0xF14E, 0x03A6, 0x097E, 0xF01C, 0x0D4A, 0xFD6E, 0xF3DF, 0x0FB6, 0xF38F, 0xFF55, 0x0CAF, 0xEFC6,
    0x09C0, 0x0195, 0xF14A, 0x0F56, 0xF6F3, 0xFBCA, 0x0EB1, 0xF08A, 0x05C3, 0x0503, 0xEF98, 0x0D78, 0xFB6C, 0xF803, 0x0FFC, 0xF250, 0x0209, 0x0822, 0xEEA8, 0x0C12, 0xFF57, 0xF4FE, 0x10AA, 0xF52F, 0xFD29,
    0x0B30, 0xEEBC, 0x08AC, 0x03B2, 0xF2C5, 0x0FEC, 0xF79B, 0xF98B, 0x0D86, 0xEFF9, 0x058F, 0x073D, 0xF092, 0x0D9D, 0xFB45, 0xF64D, 0x0E58, 0xF2C6, 0x01A0, 0x0A77, 0xF09D, 0x0B15, 0xFF01, 0xF2D6, 0x0F07,
    0xF502, 0xFE25, 0x0D76, 0xF07B, 0x0796, 0x0303, 0xF146, 0x0E33, 0xF8FA, 0xFA11, 0x0F49, 0xF177, 0x03AE, 0x061D, 0xEF8E, 0x0C99, 0xFCDD, 0xF6DE, 0x0FB1, 0xF39E, 0xFF6E, 0x0989, 0xEFE0, 0x0A11, 0x017E,
    0xF4E6, 0x0F74, 0xF5C0, 0xFB67, 0x0BA9, 0xF058, 0x075F, 0x0543, 0xF2B0, 0x0DB1, 0xF93E, 0xF841, 0x0D68, 0xF28E, 0x03C2, 0x083F, 0xF197, 0x0B6F, 0xFCED, 0xF530, 0x0E1C, 0xF46C, 0xFFDC, 0x0BBB, 0xF153,
    0x08E7, 0x00A3, 0xF303, 0x0D78, 0xF78F, 0xFCB5, 0x0D0A, 0xF24B, 0x051D, 0x03FE, 0xF1E3, 0x0C8F, 0xFB49, 0xF8FD, 0x0E28, 0xF2BE, 0x01C8, 0x073D, 0xF098, 0x0A9F, 0xFEC3, 0xF70E, 0x0E10, 0xF5D9, 0xFE29,
    0x09C0, 0xF13E, 0x0885, 0x02EC, 0xF41C, 0x0D87, 0xF804, 0xFA7D, 0x0B94, 0xF25E, 0x04F1, 0x062A, 0xF2BB, 0x0BB3, 0xFAEA, 0xF7AE, 0x0CED, 0xF44C, 0x023E, 0x0910, 0xF243, 0x08E5, 0xFE84, 0xF4C7, 0x0C70,
    0xF71E, 0xFE9F, 0x0AF2, 0xF2DA, 0x0675, 0x01C2, 0xF345, 0x0C0E, 0xF9EF, 0xFB44, 0x0C58, 0xF35E, 0x0325, 0x04CF, 0xF294, 0x0AD1, 0xFD6B, 0xF8EA, 0x0CCD, 0xF562, 0xFFA7, 0x0804, 0xF24D, 0x086F, 0x0106,
    0xF5FE, 0x0BF5, 0xF7AC, 0xFC56, 0x09AC, 0xF2F8, 0x05C6, 0x0442, 0xF440, 0x0B4D, 0xFA2E, 0xF988, 0x0B49, 0xF4FF, 0x02E2, 0x0733, 0xF40A, 0x08C7, 0xFD7D, 0xF749, 0x0B30, 0xF67F, 0x000B, 0x08DF, 0xF3C0,
    0x067A, 0x00B0, 0xF521, 0x0AB9, 0xFA24, 0xFD33, 0x0A3A, 0xF46F, 0x0351, 0x0335, 0xF479, 0x09D3, 0xFCEB, 0xFAAD, 0x0B96, 0xF57B, 0x0081, 0x061D, 0xF458, 0x0866, 0xFF68, 0xF8C9, 0x0B17, 0xF76F, 0xFD4F,
    0x0824, 0xF45C, 0x05FA, 0x0373, 0xF685, 0x09F5, 0xF9E6, 0xFADE, 0x08C1, 0xF56C, 0x039F, 0x0579, 0xF552, 0x0858, 0xFD0D, 0xF8F7, 0x09F1, 0xF7AA, 0x00F9, 0x076D, 0xF4EB, 0x0603, 0xFFC4, 0xF72E, 0x09DE,
    0xFA13, 0xFE3F, 0x08EF, 0xF54A, 0x0389, 0x028A, 0xF590, 0x0888, 0xFCCE, 0xFC22, 0x0961, 0xF65E, 0x00D1, 0x04CA, 0xF54A, 0x0785, 0xFF99, 0xF9D8, 0x09D4, 0xF815, 0xFDF8, 0x063D, 0xF5F9, 0x057E, 0x023E,
    0xF7E7, 0x08C6, 0xFA16, 0xFBDC, 0x0800, 0xF6A7, 0x0368, 0x04A2, 0xF75B, 0x0747, 0xFCEB, 0xF9A4, 0x07C6, 0xF8A1, 0x0194, 0x0647, 0xF6B0, 0x052D, 0xFF44, 0xF83C, 0x083E, 0xFA95, 0xFEB4, 0x0792, 0xF729,
    0x0341, 0x0178, 0xF793, 0x078B, 0xFD1A, 0xFC8C, 0x0810, 0xF7DE, 0x00F1, 0x0413, 0xF6CF, 0x0642, 0x001A, 0xFA75, 0x082B, 0xF960, 0xFE47, 0x0592, 0xF6FB, 0x04F5, 0x01D6, 0xF972, 0x074D, 0xFB70, 0xFBD7,
    0x0658, 0xF88B, 0x02CD, 0x0471, 0xF8A0, 0x066F, 0xFD0F, 0xFA24, 0x071D, 0xF9F7, 0x00F0, 0x05DE, 0xF7B6, 0x0423, 0xFF37, 0xF928, 0x0732, 0xFB3D, 0xFEC2, 0x06A1, 0xF807, 0x023F, 0x01A3, 0xF800, 0x06C9,
    0xFDB6, 0xFC67, 0x07B1, 0xF8B4, 0xFFBC, 0x0339, 0xF7D9, 0x0531, 0xFFD0, 0xFB29, 0x074D, 0xFA5A, 0xFD86, 0x0527, 0xF892, 0x035C, 0x0257, 0xFA0A, 0x063D, 0xFC01, 0xFC25, 0x0635, 0xF942, 0x021A, 0x0431,
    0xF894, 0x0528, 0xFE0F, 0xF9AB, 0x05CD, 0xFAEF, 0x002A, 0x05FA, 0xF8B3, 0x0349, 0x0048, 0xF8C8, 0x069A, 0xFCAF, 0xFE1A, 0x06AB, 0xF8A4, 0x00AB, 0x028D, 0xF888, 0x057F, 0xFECE, 0xFC40, 0x0718, 0xF94A,
    0xFF2D, 0x03A3, 0xF7C9, 0x045F, 0x01D4, 0xFA81, 0x06AC, 0xFB69, 0xFC96, 0x0576, 0xF8C4, 0x0344, 0x0324, 0xF945, 0x0590, 0xFC6D, 0xFAF0, 0x0659, 0xF9F5, 0x008E, 0x051E, 0xF93F, 0x0397, 0xFEE7, 0xF9DA,
    0x0621, 0xFB5C, 0xFEFC, 0x064A, 0xF863, 0x01E0, 0x018A, 0xF86F, 0x0623, 0xFE45, 0xFCE3, 0x06E6, 0xF94B, 0x00A2, 0x0329, 0xF7F9, 0x053F, 0x0013, 0xFB3E, 0x078D, 0xFA89, 0xFE1C, 0x04C5, 0xF850, 0x03DB,
    0x019C, 0xF9DE, 0x0672, 0xFC41, 0xFC1B, 0x067B, 0xF8C3, 0x0225, 0x0433, 0xF8B5, 0x0533, 0xFD8B, 0xFA70, 0x063E, 0xF9F9, 0xFFF8, 0x063A, 0xF83B, 0x0461, 0xFF94, 0xF85E, 0x070C, 0xFBB5, 0xFDD1, 0x06CB,
    0xF890, 0x01B2, 0x018C, 0xF7CC, 0x0687, 0xFDB4, 0xFC6A, 0x07AD, 0xF8C7, 0xFFC8, 0x0409, 0xF708, 0x0543, 0x00A9, 0xFA24, 0x0778, 0xF9B9, 0xFD21, 0x059A, 0xF796, 0x0421, 0x02B2, 0xF860, 0x0758, 0xFC2D,
    0xFAD4, 0x0720, 0xF88B, 0x01B5, 0x04E7, 0xF7F5, 0x0609, 0xFDF1, 0xF994, 0x0827, 0xF992, 0xFFDC, 0x0756, 0xF6F0, 0x0403, 0x0057, 0xF7CB, 0x0778, 0xFB5C, 0xFD91, 0x07F8, 0xF752, 0x0216, 0x0246, 0xF673,
    0x0780, 0xFDF1, 0xFB13, 0x08A4, 0xF812, 0xFF56, 0x0513, 0xF609, 0x0675, 0x003D, 0xF8F1, 0x098F, 0xF919, 0xFD28, 0x06BE, 0xF5BE, 0x0425, 0x02E8, 0xF7BA, 0x07E1, 0xFB6E, 0xFAFC, 0x07EF, 0xF6BE, 0x026F,
    0x0624, 0xF68F, 0x070B, 0xFD6B, 0xF883, 0x08D1, 0xF8D1, 0x0055, 0x07B4, 0xF5DF, 0x0522, 0xFFD0, 0xF6CF, 0x0968, 0xFA27, 0xFD65, 0x091F, 0xF59B, 0x024C, 0x02AE, 0xF587, 0x085B, 0xFD26, 0xFB07, 0x0A2D,
    0xF6EA, 0x001C, 0x0556, 0xF4FE, 0x07A4, 0xFFEE, 0xF87B, 0x0A97, 0xF856, 0xFD92, 0x077A, 0xF506, 0x05A3, 0x0288, 0xF68B, 0x0A04, 0xF9E9, 0xFA67, 0x098C, 0xF58A, 0x0373, 0x059A, 0xF5A6, 0x084E, 0xFC0E,
    0xF87D, 0x0A0E, 0xF6EE, 0x015F, 0x0844, 0xF484, 0x0652, 0xFFBA, 0xF6A0, 0x0A96, 0xF9F4, 0xFE31, 0x09BA, 0xF497, 0x045F, 0x0218, 0xF4A0, 0x0AB8, 0xFC1D, 0xFACB, 0x0AFE, 0xF55F, 0x011C, 0x0515, 0xF407,
    0x091E, 0xFECD, 0xF8DF, 0x0B45, 0xF67A, 0xFE50, 0x07F7, 0xF3A6, 0x070A, 0x025D, 0xF650, 0x0B13, 0xF869, 0xFBCB, 0x09DA, 0xF3F7, 0x0580, 0x04F0, 0xF3FF, 0x0A2C, 0xFB87, 0xF8B9, 0x0B41, 0xF550, 0x01DA,
    0x07FC, 0xF41A, 0x0839, 0xFDB0, 0xF6C7, 0x0C57, 0xF763, 0xFFAE, 0x0A43, 0xF316, 0x0639, 0x016F, 0xF46B, 0x0B97, 0xFA84, 0xFC2D, 0x0B8D, 0xF34F, 0x0326, 0x043E, 0xF303, 0x0B4A, 0xFCF1, 0xF8FD, 0x0BFF,
    0xF4BC, 0xFFA3, 0x0763, 0xF31D, 0x0902, 0x0065, 0xF69E, 0x0C6B, 0xF689, 0xFD59, 0x0A64, 0xF2A0, 0x06C2, 0x03E7, 0xF453, 0x0B0E, 0xF977, 0xFA3E, 0x0B7D, 0xF404, 0x0430, 0x064C, 0xF2A9, 0x0A8A, 0xFC27,
    0xF71C, 0x0C78, 0xF60F, 0x012B, 0x0905, 0xF2BF, 0x083C, 0xFFE1, 0xF540, 0x0D2A, 0xF846, 0xFDAF, 0x0B9F, 0xF1A5, 0x04D6, 0x03AE, 0xF360, 0x0BBE, 0xFB23, 0xFB26, 0x0C19, 0xF31C, 0x02C6, 0x0699, 0xF1F9,
    0x0B7D, 0xFE87, 0xF6FA, 0x0D39, 0xF53F, 0xFEEC, 0x08C0, 0xF264, 0x0908, 0x0199, 0xF4B4, 0x0CDA, 0xF75F, 0xFBBA, 0x0BB8, 0xF2F8, 0x0613, 0x0529, 0xF30A, 0x0B85, 0xFA4D, 0xF8C1, 0x0C29, 0xF3EF, 0x036C,
    0x07CF, 0xF1C2, 0x0989, 0xFE25, 0xF5C2, 0x0DB0, 0xF6D5, 0xFF34, 0x0A46, 0xF10E, 0x0778, 0x012A, 0xF3EC, 0x0DB1, 0xF8DD, 0xFBDD, 0x0C14, 0xF1D5, 0x03B8, 0x0550, 0xF241, 0x0C1C, 0xFC13, 0xF8B9, 0x0D2D,
    0xF301, 0x016B, 0x07EC, 0xF1A4, 0x0ABA, 0x0006, 0xF598, 0x0CFB, 0xF562, 0xFDD0, 0x0A38, 0xF217, 0x0830, 0x0261, 0xF352, 0x0CA5, 0xF8BD, 0xFA4F, 0x0CF0, 0xF2D9, 0x04C9, 0x05E8, 0xF1F6, 0x0B03, 0xFBA4,
    0xF878, 0x0D40, 0xF474, 0x01E6, 0x08B8, 0xF07B, 0x0914, 0xFF60, 0xF4B7, 0x0DA9, 0xF743, 0xFE0E, 0x0A82, 0xF10D, 0x06A2, 0x0277, 0xF2F0, 0x0D9E, 0xF99C, 0xFA8C, 0x0C4F, 0xF231, 0x0368, 0x05EE, 0xF257,
    0x0B16, 0xFD8E, 0xF771, 0x0CB4, 0xF40D, 0x000B, 0x0910, 0xF171, 0x09EB, 0x00DE, 0xF4BF, 0x0CEC, 0xF744, 0xFC4D, 0x0A8E, 0xF28A, 0x077E, 0x03AB, 0xF299, 0x0C47, 0xF919, 0xF94E, 0x0D58, 0xF3E6, 0x0338,
    0x06C9, 0xF193, 0x0A07, 0xFC99, 0xF6E4, 0x0D50, 0xF5C5, 0x0073, 0x093D, 0xF111, 0x079E, 0x0106, 0xF4A6, 0x0D64, 0xF911, 0xFD69, 0x0AA7, 0xF16E, 0x05A9, 0x03EB, 0xF328, 0x0C76, 0xFB53, 0xF9F7, 0x0C2A,
    0xF2F0, 0x01C3, 0x06CF, 0xF292, 0x0AC7, 0xFE79, 0xF74C, 0x0C79, 0xF48A, 0xFEAA, 0x09F4, 0xF299, 0x0858, 0x026F, 0xF489, 0x0B8A, 0xF80A, 0xFC2F, 0x0B14, 0xF303, 0x0606, 0x04F2, 0xF21E, 0x0AEC, 0xFAA9,
    0xF8AA, 0x0D14, 0xF532, 0x029A, 0x075E, 0xF1DD, 0x08BF, 0xFE5A, 0xF62F, 0x0D3E, 0xF709, 0xFEF7, 0x094D, 0xF1D6, 0x069B, 0x0187, 0xF4B1, 0x0C50, 0xF9E5, 0xFB91, 0x0ABA, 0xF2FE, 0x047B, 0x04D9, 0xF315,
    0x0BFD, 0xFCE4, 0xF801, 0x0B85, 0xF501, 0x0094, 0x0712, 0xF39B, 0x096C, 0xFFEA, 0xF6A2, 0x0BF7, 0xF6D1, 0xFDA6, 0x0A52, 0xF3A5, 0x073C, 0x032D, 0xF455, 0x0B11, 0xF9FC, 0xFB0C, 0x0B1E, 0xF479, 0x045B,
    0x057D, 0xF256, 0x09EA, 0xFCAC, 0xF7DA, 0x0C69, 0xF6F0, 0x00F5, 0x0786, 0xF2EA, 0x0711, 0xFFBD, 0xF678, 0x0C63, 0xF8E8, 0xFD72, 0x0928, 0xF2E1, 0x04F8, 0x02E3, 0xF4D6, 0x0B4C, 0xFBC2, 0xFA58, 0x0A03,
    0xF43F, 0x02B6, 0x05D1, 0xF404, 0x09B8, 0xFE8A, 0xF7DE, 0x0A92, 0xF6BB, 0xFF5D, 0x07C7, 0xF473, 0x07F1, 0x009A, 0xF60A, 0x0A0F, 0xF835, 0xFCA7, 0x0A59, 0xF4F9, 0x04C4, 0x03CA, 0xF44F, 0x0994, 0xFAF8,
    0xFA78, 0x0B46, 0xF66A, 0x02EF, 0x0552, 0xF382, 0x0838, 0xFE26, 0xF83F, 0x0BAB, 0xF877, 0xFF58, 0x077D, 0xF421, 0x05D8, 0x00CC, 0xF740, 0x0AF0, 0xFA4B, 0xFC6D, 0x092B, 0xF4B0, 0x0350, 0x03DA, 0xF5F5,
    0x0A0E, 0xFCC4, 0xF9BA, 0x0963, 0xF688, 0x00E2, 0x0635, 0xF584, 0x07EC, 0xFFAB, 0xF7BF, 0x08D8, 0xF853, 0xFE70, 0x082A, 0xF616, 0x05FF, 0x01DB, 0xF607, 0x0971, 0xFA7D, 0xFC3F, 0x096A, 0xF713, 0x0348,
    0x03FA, 0xF5D1, 0x0775, 0xFD26, 0xFA2E, 0x09EA, 0xF8B8, 0x00C6, 0x05A6, 0xF54C, 0x05B7, 0xFFAA, 0xF875, 0x09D3, 0xFABC, 0xFDD4, 0x06AB, 0xF58C, 0x03E1, 0x01F1, 0xF709, 0x0998, 0xFC1A, 0xFB4D, 0x081D,
    0xF6A8, 0x01BD, 0x0470, 0xF6EE, 0x0794, 0xFEB8, 0xF945, 0x0895, 0xF84F, 0xFF58, 0x06C8, 0xF6E8, 0x05A0, 0x0054, 0xF7CF, 0x07CE, 0xFA73, 0xFD7A, 0x07EB, 0xF80F, 0x03B7, 0x0210, 0xF67F, 0x0754, 0xFCBA,
    0xFAD6, 0x085A, 0xF8CC, 0x00CB, 0x03FB, 0xF653, 0x054E, 0xFEFA, 0xFA13, 0x0840, 0xFA27, 0xFED0, 0x05B1, 0xF6C4, 0x0411, 0x01A1, 0xF8BE, 0x079B, 0xFC85, 0xFCD2, 0x069B, 0xF7AB, 0x021F, 0x0367, 0xF7DB,
    0x0782, 0xFE32, 0xFA94, 0x0714, 0xF92E, 0xFFE5, 0x04E0, 0xF846, 0x04CE, 0xFFA9, 0xF900, 0x067D, 0xFA7D, 0xFDEB, 0x068C, 0xF8E8, 0x036F, 0x01B9, 0xF813, 0x0580, 0xFCDF, 0xFCAC, 0x0720, 0xFA1D, 0x01B0,
    0x0384, 0xF7EC, 0x04E2, 0xFEB5, 0xFAFE, 0x07C4, 0xFB2B, 0xFE9C, 0x046F, 0xF7F3, 0x038C, 0x0129, 0xFA67, 0x06F8, 0xFC25, 0xFD00, 0x04F4, 0xF89B, 0x01C6, 0x0348, 0xF98B, 0x05D5, 0xFE8A, 0xFB74, 0x055C,
    0xF9E4, 0x0077, 0x0463, 0xF9D9, 0x049B, 0xFFFA, 0xFA09, 0x0578, 0xFBDA, 0xFE11, 0x058C, 0xFA1D, 0x0305, 0x0128, 0xF8E4, 0x04AF, 0xFD11, 0xFD14, 0x05BF, 0xFAF9, 0x005B, 0x0292, 0xF8ED, 0x0367, 0xFF1F,
    0xFB79, 0x0626, 0xFBFF, 0xFED1, 0x0330, 0xF8BF, 0x029C, 0x0133, 0xFADD, 0x05B8, 0xFD36, 0xFD17, 0x0448, 0xFA41, 0x0118, 0x0267, 0xFACD, 0x04DF, 0xFEB1, 0xFB50, 0x04A5, 0xFA85, 0xFF16, 0x0411, 0xFA7A,
    0x032F, 0x002F, 0xFA0C, 0x03CF, 0xFC42, 0xFE32, 0x04E5, 0xFB2D, 0x01D4, 0x0179, 0xF9AC, 0x03AC, 0xFE75, 0xFCA8, 0x05C4, 0xFC0B, 0x0003, 0x026E, 0xF9F7, 0x030D, 0xFFCF, 0xFBFE, 0x05A3, 0xFC85, 0xFE08,
    0x03DF, 0xF99D, 0x0124, 0x015F, 0xFB1B, 0x044B, 0xFE36, 0xFCE2, 0x03E0, 0xFA94, 0x007A, 0x0389, 0xFAEC, 0x037F, 0xFFC1, 0xFAFC, 0x03FB, 0xFC1E, 0xFE70, 0x04BC, 0xFB3F, 0x02DA, 0x010A, 0xFA1D, 0x0425,
    0xFD3F, 0xFCC1, 0x04F5, 0xFBCF, 0x00C4, 0x0242, 0xF9AE, 0x02F6, 0xFF2F, 0xFC9F, 0x05B8, 0xFCB0, 0xFEE2, 0x0313, 0xF989, 0x01AB, 0x00A9, 0xFB46, 0x0525, 0xFDCD, 0xFD4E, 0x0360, 0xFA30, 0x0097, 0x01DD,
    0xFB05, 0x04CF, 0xFF11, 0xFB88, 0x0458, 0xFB44, 0xFF38, 0x039D, 0xFAC8, 0x037B, 0x002B, 0xFA6D, 0x0470, 0xFC4B, 0xFDB8, 0x0551, 0xFB3E, 0x0237, 0x01C0, 0xF954, 0x03F6, 0xFEA4, 0xFCAE, 0x05FE, 0xFBAF,
    0x004E, 0x033E, 0xF8D9, 0x02FF, 0xFFB3, 0xFB91, 0x0650, 0xFD46, 0xFE30, 0x0421, 0xF99A, 0x017D, 0x0174, 0xFA77, 0x05CB, 0xFE26, 0xFCB1, 0x04C6, 0xF9BC, 0xFFEC, 0x0330, 0xFA1B, 0x04AC, 0xFFC3, 0xFAC5,
    0x0538, 0xFB1A, 0xFEF2, 0x04F9, 0xF9FA, 0x03B1, 0x0170, 0xF932, 0x04D9, 0xFCBB, 0xFD26, 0x05C3, 0xFA92, 0x0191, 0x0227, 0xF937, 0x03FF, 0xFE1C, 0xFBCE, 0x0699, 0xFB39, 0xFFA1, 0x0419, 0xF876, 0x0361,
    0x008B, 0xFA72, 0x0658, 0xFCBC, 0xFE16, 0x04F0, 0xF83A, 0x01C5, 0x0280, 0xF987, 0x05EE, 0xFDFA, 0xFBBB, 0x05F2, 0xF996, 0x0040, 0x03E9, 0xF8F2, 0x0577, 0xFF6D, 0xF9EA, 0x061D, 0xFA7E, 0xFEDC, 0x05BF,
    0xF97C, 0x035D, 0x013E, 0xF8C3, 0x05AA, 0xFC74, 0xFCE1, 0x06C0, 0xF91E, 0x023D, 0x02B3, 0xF7C8, 0x0541, 0xFDB6, 0xFB24, 0x0753, 0xFA98, 0x0003, 0x04B1, 0xF7E0, 0x044E, 0x0058, 0xFA19, 0x079E, 0xFB3F,
    0xFD9A, 0x05F6, 0xF7DC, 0x02B4, 0x027E, 0xF937, 0x0706, 0xFD61, 0xFBCA, 0x0658, 0xF827, 0x00E2, 0x041B, 0xF7FA, 0x0627, 0xFF29, 0xF93E, 0x0710, 0xFA3A, 0xFEB2, 0x05C9, 0xF7DF, 0x048C, 0x0130, 0xF7E8,
    0x06FF, 0xFB74, 0xFC80, 0x07DB, 0xF8E2, 0x02D3, 0x0337, 0xF734, 0x0615, 0xFD65, 0xFAB1, 0x0861, 0xF941, 0x0055, 0x04AF, 0xF655, 0x057A, 0xFFEF, 0xF974, 0x08D9, 0xFADB, 0xFDC5, 0x062E, 0xF67E, 0x0404,
    0x01C6, 0xF7FB, 0x082B, 0xFC60, 0xFBCA, 0x074D, 0xF75C, 0x020B, 0x046D, 0xF721, 0x0719, 0xFDFD, 0xFA12, 0x07B3, 0xF7FF, 0xFFA7, 0x0662, 0xF6F6, 0x0620, 0x0063, 0xF7F3, 0x07CA, 0xFA3A, 0xFD76, 0x080E,
    0xF777, 0x03F1, 0x0285, 0xF66B, 0x07F2, 0xFBE5, 0xFB77, 0x0914, 0xF801, 0x017F, 0x04D9, 0xF5D0, 0x06D7, 0xFE41, 0xF96B, 0x0A0F, 0xF947, 0xFF4A, 0x0673, 0xF578, 0x052F, 0x014C, 0xF7DD, 0x097B, 0xFABA,
    0xFCFB, 0x07AA, 0xF5EE, 0x0317, 0x0399, 0xF68C, 0x0921, 0xFD71, 0xF97E, 0x089C, 0xF748, 0x00DC, 0x05CF, 0xF626, 0x072B, 0xFF42, 0xF79E, 0x095B, 0xF8AB, 0xFE6E, 0x0863, 0xF60D, 0x0566, 0x01D4, 0xF6C8,
    0x08CB, 0xFB0C, 0xFC57, 0x0936, 0xF634, 0x02A3, 0x0389, 0xF538, 0x0823, 0xFCEA, 0xF9A0, 0x0A5A, 0xF7FB, 0x0083, 0x0590, 0xF4A7, 0x0701, 0xFF7C, 0xF8BC, 0x0A80, 0xF91A, 0xFDB9, 0x0795, 0xF4B1, 0x04DA,
    0x0290, 0xF6D4, 0x09E0, 0xFB4B, 0xFB2C, 0x087B, 0xF5F4, 0x027E, 0x056B, 0xF584, 0x0916, 0xFDC3, 0xF868, 0x09D7, 0xF781, 0x0031, 0x06DA, 0xF586, 0x06A7, 0xFFCA, 0xF68C, 0x0A0B, 0xF8F9, 0xFD38, 0x0941,
    0xF5CB, 0x04CD, 0x02BB, 0xF540, 0x08BC, 0xFBD2, 0xFB73, 0x0A56, 0xF65E, 0x01BF, 0x04F3, 0xF4D0, 0x0811, 0xFE5F, 0xF8BA, 0x0AFD, 0xF88A, 0xFEE7, 0x06D7, 0xF466, 0x05F1, 0x00DC, 0xF6ED, 0x0AC8, 0xF977,
    0xFC31, 0x0920, 0xF519, 0x0426, 0x0416, 0xF622, 0x09D3, 0xFC46, 0xFA2F, 0x09F2, 0xF5FD, 0x0192, 0x060F, 0xF519, 0x0800, 0xFE2C, 0xF7A9, 0x0A16, 0xF7B1, 0xFF27, 0x07DE, 0xF4E9, 0x0633, 0x00AE, 0xF5CE,
    0x09D5, 0xFA5D, 0xFC7B, 0x09BF, 0xF5B3, 0x0374, 0x0394, 0xF484, 0x08FA, 0xFCD8, 0xF9FB, 0x0ABA, 0xF6C7, 0x011B, 0x061E, 0xF45A, 0x0775, 0xFF5E, 0xF838, 0x0ABA, 0xF83A, 0xFE04, 0x077F, 0xF41D, 0x05ED,
    0x01F6, 0xF68D, 0x0A6E, 0xFA59, 0xFB24, 0x08FA, 0xF54F, 0x0376, 0x04BB, 0xF544, 0x097D, 0xFC9B, 0xF8ED, 0x09C3, 0xF670, 0x00C8, 0x0708, 0xF4B2, 0x0798, 0xFF36, 0xF6B8, 0x0AA8, 0xF8AA, 0xFE1A, 0x08A1,
    0xF4FD, 0x0527, 0x0130, 0xF564, 0x0A3A, 0xFB11, 0xFBC6, 0x0A47, 0xF600, 0x025D, 0x03CA, 0xF44F, 0x08B2, 0xFD50, 0xF9E4, 0x0A7D, 0xF701, 0x0035, 0x066F, 0xF3F6, 0x068F, 0x00A3, 0xF79A, 0x0A2A, 0xF8E6,
    0xFD2D, 0x07DF, 0xF508, 0x0537, 0x02FE, 0xF5FA, 0x09AE, 0xFB54, 0xFAA7, 0x09B5, 0xF63A, 0x023F, 0x0563, 0xF576, 0x0848, 0xFD75, 0xF8A1, 0x09C1, 0xF756, 0x002C, 0x079B, 0xF56A, 0x066A, 0xFFF5, 0xF676,
    0x09A5, 0xF952, 0xFE00, 0x0942, 0xF58A, 0x0464, 0x0296, 0xF58C, 0x093A, 0xFC3F, 0xFB3E, 0x0A2A, 0xF628, 0x0148, 0x051D, 0xF48D, 0x07B3, 0xFE89, 0xF934, 0x0A88, 0xF7BA, 0xFECC, 0x0689, 0xF508, 0x067E,
    0x0156, 0xF73E, 0x09C9, 0xF9A8, 0xFC64, 0x0874, 0xF589, 0x0434, 0x03AD, 0xF5CC, 0x08AC, 0xFC39, 0xFA13, 0x0939, 0xF6CC, 0x01DF, 0x05E1, 0xF5EC, 0x072D, 0xFE33, 0xF88A, 0x09AB, 0xF8F0, 0xFF3F, 0x07B5,
    0xF55B, 0x04FC, 0x009C, 0xF70F, 0x094A, 0xFACE, 0xFCBB, 0x088D, 0xF670, 0x0307, 0x0309, 0xF56E, 0x0874, 0xFD69, 0xFAB2, 0x096C, 0xF7C7, 0x007D, 0x0560, 0xF5D0, 0x0717, 0xFF7B, 0xF8F5, 0x0946, 0xF8D7,
    0xFE12, 0x0698, 0xF634, 0x04EF, 0x02E0, 0xF78B, 0x0862, 0xFB1C, 0xFC01, 0x0810, 0xF64A, 0x02D4, 0x048C, 0xF6F0, 0x0747, 0xFD2B, 0xF9E2, 0x0814, 0xF80C, 0x0074, 0x0605, 0xF6C2, 0x059D, 0xFF99, 0xF80F,
    0x0822, 0xFA32, 0xFE6C, 0x07B1, 0xF6CF, 0x036B, 0x0199, 0xF750, 0x084E, 0xFCB2, 0xFC99, 0x0826, 0xF771, 0x0172, 0x0375, 0xF6C0, 0x06C8, 0xFEB8, 0xFAD8, 0x0805, 0xF871, 0xFF6C, 0x0566, 0xF70B, 0x0578,
    0x00BD, 0xF8D4, 0x07AC, 0xFA2C, 0xFD46, 0x06F8, 0xF785, 0x03C5, 0x030A, 0xF84E, 0x0740, 0xFBF9, 0xFB4D, 0x07AB, 0xF808, 0x01C6, 0x04D1, 0xF750, 0x05AF, 0xFE1B, 0xF9E5, 0x0781, 0xF9DE, 0xFFFD, 0x05EF,
    0xF70D, 0x043A, 0x0034, 0xF8AD, 0x07B3, 0xFB86, 0xFE00, 0x06DA, 0xF7EC, 0x022F, 0x01CA, 0xF82B, 0x06E8, 0xFD94, 0xFC09, 0x079E, 0xF8C7, 0x005D, 0x03C2, 0xF7CD, 0x05B2, 0xFF58, 0xFAA4, 0x0713, 0xF9FD,
    0xFE8D, 0x0586, 0xF7C6, 0x03D5, 0x01A3, 0xF8EA, 0x0669, 0xFB8D, 0xFD1A, 0x062A, 0xF8E8, 0x02E1, 0x0323, 0xF898, 0x04D0, 0xFDB1, 0xFB92, 0x0674, 0xFA4A, 0x0061, 0x04A1, 0xF876, 0x03E5, 0xFF9D, 0xFA20,
    0x06B2, 0xFBE9, 0xFECD, 0x0540, 0xF8B0, 0x0286, 0x0110, 0xF9C6, 0x05EE, 0xFD44, 0xFCE9, 0x05C1, 0xF8ED, 0x00E4, 0x02E4, 0xF8C2, 0x056D, 0xFF4F, 0xFBD2, 0x05BE, 0xFA94, 0xFF1D, 0x03B2, 0xF8E7, 0x03A0,
    0x00E0, 0xFB01, 0x0555, 0xFC37, 0xFDB1, 0x04BC, 0xF9A9, 0x0278, 0x0254, 0xF992, 0x04E2, 0xFD1D, 0xFC84, 0x0517, 0xFAD7, 0x0122, 0x0305, 0xF9DB, 0x031A, 0xFEB7, 0xFB5F, 0x04D4, 0xFC25, 0xFF9F, 0x0456,
    0xF9E4, 0x01B1, 0x0092, 0xFAEF, 0x0537, 0xFDA0, 0xFD96, 0x046B, 0xFA7A, 0x0059, 0x0198, 0xFA66, 0x0428, 0xFF34, 0xFC21, 0x0496, 0xFB24, 0xFF60, 0x02DE, 0xFAA4, 0x03C9, 0x00D0, 0xFBCE, 0x041F, 0xFCAF,
    0xFE05, 0x0424, 0xFACE, 0x01FB, 0x0210, 0xFAD2, 0x03A7, 0xFDED, 0xFCFB, 0x03DC, 0xFB9B, 0x00C4, 0x028A, 0xFA73, 0x0282, 0xFECD, 0xFB83, 0x0479, 0xFD33, 0xFF6F, 0x03D6, 0xFAC5, 0x0143, 0x0000, 0xFB2C,
    0x0390, 0xFE07, 0xFE5A, 0x038C, 0xFB34, 0x00C1, 0x01D6, 0xFB44, 0x033F, 0xFF5A, 0xFD15, 0x033B, 0xFC17, 0xFF53, 0x0221, 0xFB64, 0x0275, 0x0112, 0xFBEF, 0x02E7, 0xFD26, 0xFD99, 0x030B, 0xFB50, 0x0185,
    0x018F, 0xFBA6, 0x032C, 0xFDB6, 0xFCFD, 0x03D7, 0xFCF9, 0x0059, 0x0242, 0xFB29, 0x019C, 0xFFE1, 0xFC1F, 0x0384, 0xFDC9, 0xFF1D, 0x0357, 0xFB87, 0x00F0, 0x005F, 0xFC85, 0x0311, 0xFEFA, 0xFE7E, 0x0331,
    0xFBD4, 0xFF70, 0x01EE, 0xFBB0, 0x028A, 0xFF5A, 0xFD45, 0x02D7, 0xFD36, 0xFE79, 0x0216, 0xFC27, 0x013B, 0x0137, 0xFB96, 0x02B7, 0xFDBB, 0xFDE2, 0x02C5, 0xFC66, 0x0069, 0x01F1, 0xFC68, 0x013E, 0xFED2,
    0xFC44, 0x0385, 0xFDBE, 0xFF93, 0x02F5, 0xFB86, 0x0103, 0x0047, 0xFC56, 0x0334, 0xFE9A, 0xFF02, 0x0365, 0xFBCD, 0xFFC0, 0x011E, 0xFC2D, 0x025D, 0xFF86, 0xFD6C, 0x0354, 0xFC93, 0xFE1B, 0x0299, 0xFC26,
    0x01C1, 0x00C9, 0xFCB2, 0x0317, 0xFDAD, 0xFDCE, 0x02C8, 0xFC2E, 0x0110, 0x01BA, 0xFC02, 0x026C, 0xFE58, 0xFC99, 0x030B, 0xFDC1, 0x003C, 0x0304, 0xFB9A, 0x01D7, 0xFFFC, 0xFBF6, 0x0308, 0xFDAA, 0xFE94,
    0x034F, 0xFBAF, 0x0044, 0x017F, 0xFBB0, 0x0317, 0xFF6E, 0xFE00, 0x0304, 0xFC00, 0xFF46, 0x01D8, 0xFB57, 0x0212, 0x00A6, 0xFC79, 0x031F, 0xFD34, 0xFE49, 0x02DA, 0xFBC6, 0x01FD, 0x018C, 0xFC27, 0x0314,
    0xFD9D, 0xFD46, 0x03CD, 0xFC38, 0x002E, 0x0308, 0xFB85, 0x0238, 0xFF35, 0xFC52, 0x035F, 0xFCD2, 0xFF39, 0x030D, 0xFB59, 0x0152, 0x0041, 0xFB41, 0x0398, 0xFE39, 0xFE32, 0x0395, 0xFB7E, 0x005B, 0x0170,
    0xFADB, 0x02F8, 0xFF68, 0xFD16, 0x03EE, 0xFC53, 0xFF46, 0x02A9, 0xFB07, 0x0265, 0x0127, 0xFC21, 0x045B, 0xFCEB, 0xFDF6, 0x03AB, 0xFB1E, 0x01BB, 0x01AF, 0xFBCC, 0x0344, 0xFE48, 0xFCBA, 0x0449, 0xFBE7,
    0x00B6, 0x037B, 0xFA90, 0x031B, 0xFECD, 0xFBFA, 0x046C, 0xFCE8, 0xFF30, 0x03C9, 0xFA66, 0x0174, 0x00A4, 0xFA92, 0x0474, 0xFDBF, 0xFD7D, 0x04AF, 0xFAB9, 0x0060, 0x0267, 0xFA4B, 0x0398, 0xFF0C, 0xFCC0,
    0x054C, 0xFB78, 0xFF07, 0x035A, 0xF9C9, 0x030D, 0x00BA, 0xFB77, 0x04F2, 0xFC36, 0xFD1D, 0x0455, 0xFA6C, 0x01E5, 0x02A4, 0xFA80, 0x0482, 0xFD30, 0xFBDC, 0x0558, 0xFB3F, 0x008C, 0x0391, 0xF9BA, 0x03B2,
    0xFED9, 0xFAEE, 0x054A, 0xFBEA, 0xFF9A, 0x04A6, 0xF9CC, 0x0260, 0x00B4, 0xF9D2, 0x053F, 0xFD5E, 0xFDAB, 0x05A3, 0xF9FB, 0x015A, 0x02D7, 0xF93F, 0x04D8, 0xFEEC, 0xFBE4, 0x057A, 0xFA46, 0xFFD8, 0x03B4,
    0xF939, 0x0441, 0x00BC, 0xFB02, 0x0537, 0xFB85, 0xFE10, 0x049C, 0xF8FD, 0x0280, 0x0226, 0xF987, 0x0593, 0xFCCA, 0xFBE6, 0x05B8, 0xF969, 0x0193, 0x0383, 0xF8EB, 0x047A, 0xFE91, 0xFB51, 0x05C9, 0xFB33,
    0xFFC3, 0x04F3, 0xF8CC, 0x0380, 0x0027, 0xF9C9, 0x0685, 0xFBEA, 0xFE17, 0x05D3, 0xF8DD, 0x01F3, 0x0203, 0xF8E0, 0x0570, 0xFD92, 0xFC64, 0x0610, 0xF978, 0x0068, 0x0364, 0xF83A, 0x053A, 0xFFA4, 0xFACB,
    0x06CA, 0xFA90, 0xFF06, 0x04B6, 0xF880, 0x03B2, 0x0198, 0xF965, 0x0629, 0xFBDC, 0xFC9F, 0x063E, 0xF8AE, 0x02F7, 0x032E, 0xF832, 0x059C, 0xFD62, 0xFAB0, 0x06C6, 0xF9D9, 0x00B1, 0x04D3, 0xF7DD, 0x0475,
    0xFF6D, 0xF9E3, 0x070E, 0xFBA6, 0xFF07, 0x05DE, 0xF7D9, 0x02F4, 0x00B8, 0xF891, 0x0689, 0xFD0A, 0xFD1F, 0x0630, 0xF86A, 0x014E, 0x032D, 0xF775, 0x05FF, 0xFE6F, 0xFACC, 0x0785, 0xF910, 0xFF78, 0x04ED,
    0xF7F5, 0x0566, 0x00C9, 0xFA0C, 0x06FE, 0xFA9A, 0xFE07, 0x05BB, 0xF7E4, 0x03D6, 0x024B, 0xF821, 0x067A, 0xFC75, 0xFBA2, 0x0707, 0xF8BA, 0x0199, 0x03E4, 0xF7B8, 0x060C, 0xFDFF, 0xFA59, 0x07B5, 0xF9AE,
    0x0051, 0x0607, 0xF71B, 0x0486, 0x0043, 0xF88C, 0x077D, 0xFBC8, 0xFE05, 0x0657, 0xF744, 0x0268, 0x026D, 0xF818, 0x0790, 0xFD9B, 0xFC1D, 0x076F, 0xF7F5, 0x00F3, 0x042A, 0xF7A6, 0x0663, 0xFEE8, 0xFA3C,
    0x07CB, 0xF90D, 0xFEB3, 0x059C, 0xF752, 0x0502, 0x01BC, 0xF85E, 0x0729, 0xFB46, 0xFD1B, 0x06AF, 0xF795, 0x03B5, 0x0336, 0xF7B0, 0x06AB, 0xFCA8, 0xFB22, 0x0818, 0xF91C, 0x0132, 0x0524, 0xF6E8, 0x0591,
    0xFECF, 0xF905, 0x07F5, 0xFA41, 0xFF44, 0x064B, 0xF6B3, 0x0403, 0x014B, 0xF811, 0x0832, 0xFC4A, 0xFD26, 0x0758, 0xF787, 0x0276, 0x0267, 0xF7B4, 0x078D, 0xFDD8, 0xFB13, 0x07A6, 0xF861, 0x0012, 0x04BA,
    0xF6AE, 0x0629, 0xFFFA, 0xF9CC, 0x0820, 0xF978, 0xFE00, 0x066D, 0xF79B, 0x04DD, 0x0242, 0xF83A, 0x0767, 0xFB85, 0xFC7A, 0x0731, 0xF837, 0x032A, 0x0390, 0xF6C2, 0x06B3, 0xFDAD, 0xFA9A, 0x0800, 0xF965,
    0x00E2, 0x056D, 0xF74E, 0x04AE, 0xFF4E, 0xF8F3, 0x080B, 0xFB00, 0xFE6B, 0x069A, 0xF6F6, 0x03BF, 0x01C2, 0xF7F5, 0x0809, 0xFC61, 0xFC64, 0x0742, 0xF757, 0x01A7, 0x0367, 0xF6F8, 0x06C3, 0xFEEF, 0xFA4B,
    0x07A7, 0xF8B9, 0xFFA5, 0x05AD, 0xF747, 0x056B, 0x008E, 0xF8D4, 0x0706, 0xFA25, 0xFD72, 0x06E0, 0xF7EE, 0x043D, 0x02E9, 0xF779, 0x0679, 0xFC08, 0xFB92, 0x07A2, 0xF8A2, 0x01E9, 0x042A, 0xF6F2, 0x05ED,
    0xFE0E, 0xF9EF, 0x0867, 0xFA2E, 0xFFAA, 0x0506, 0xF6FF, 0x0479, 0x0016, 0xF8E0, 0x07D1, 0xFB74, 0xFD6D, 0x0674, 0xF773, 0x0332, 0x02A8, 0xF7F9, 0x071F, 0xFD8F, 0xFBA1, 0x06DB, 0xF861, 0x00A3, 0x045E,
    0xF787, 0x069D, 0xFF84, 0xF9DB, 0x0731, 0xF916, 0xFF4A, 0x059D, 0xF82D, 0x0526, 0x015E, 0xF8A9, 0x06E5, 0xFB5E, 0xFCF2, 0x070B, 0xF84B, 0x02F0, 0x02DD, 0xF7B4, 0x05D5, 0xFD35, 0xFB79, 0x07AB, 0xF940,
    0x017F, 0x0410, 0xF761, 0x0550, 0xFF59, 0xFA0E, 0x0835, 0xFAE1, 0xFF82, 0x04F7, 0xF746, 0x02FA, 0x0243
};

/* USER CODE END PV */

void SystemClock_Config(void);
static void MX_GPIO_Init(void);
static void MX_USART3_UART_Init(void);
static void MX_SPI1_Init(void);
static void MX_TIM1_Init(void);

/* USER CODE BEGIN 0 */
//__attribute__((always_inline))
uint8_t get_spi_byte(void)
{
	uint8_t data;
	HAL_SPI_Receive(&hspi1, &data, 1, 100);
	while(hspi1.State == HAL_SPI_STATE_BUSY);
	return data;
}

#define PIN_LOW_BSSR(pin) ((uint32_t)pin << 16U)
#define PIN_HIGH_BSSR(pin) (pin)

/* USER CODE END 0 */

int main(void)
{

  /* MCU Configuration--------------------------------------------------------*/

  /* Reset of all peripherals, Initializes the Flash interface and the Systick. */
  HAL_Init();

  /* Configure the system clock */
  SystemClock_Config();

  /* Initialize all configured peripherals */
  MX_GPIO_Init();
  MX_USART3_UART_Init();
  MX_SPI1_Init();
  MX_TIM1_Init();
  /* USER CODE BEGIN 2 */
  //int strindex = 0;
  //char strbuf[6000];
  //char strbuf2[100];

  //set CS initially to:
  //HAL_GPIO_WritePin(SNSS_GPIO_Port, SNSS_Pin, GPIO_PIN_SET); // NSS1 Default Set

  //DE1 GPIO data to send
  //HAL_GPIO_WritePin(AUDIO_READY_GPIO_PORT, AUDIO_READY, GPIO_PIN_RESET);
  //HAL_GPIO_WritePin(AUDIO_CLEAR_BUF_GPIO_PORT, AUDIO_CLEAR_BUF, GPIO_PIN_RESET); //set to 0 before sending every NUMVALS

  /*
  HAL_GPIO_WritePin(AUDIO_GPIO_PINS_0_3_PORT, AUDIO_GPIO_0, GPIO_PIN_RESET);
  HAL_GPIO_WritePin(AUDIO_GPIO_PINS_0_3_PORT, AUDIO_GPIO_1, GPIO_PIN_RESET);
  HAL_GPIO_WritePin(AUDIO_GPIO_PINS_0_3_PORT, AUDIO_GPIO_2, GPIO_PIN_RESET);
  HAL_GPIO_WritePin(AUDIO_GPIO_PINS_0_3_PORT, AUDIO_GPIO_3, GPIO_PIN_RESET);

  HAL_GPIO_WritePin(AUDIO_GPIO_PINS_4_8_PORT, AUDIO_GPIO_4, GPIO_PIN_RESET);
  HAL_GPIO_WritePin(AUDIO_GPIO_PINS_4_8_PORT, AUDIO_GPIO_5, GPIO_PIN_RESET);
  HAL_GPIO_WritePin(AUDIO_GPIO_PINS_4_8_PORT, AUDIO_GPIO_6, GPIO_PIN_RESET);
  HAL_GPIO_WritePin(AUDIO_GPIO_PINS_4_8_PORT, AUDIO_GPIO_7, GPIO_PIN_RESET);

  HAL_GPIO_WritePin(AUDIO_GPIO_PINS_4_8_PORT, AUDIO_GPIO_8, GPIO_PIN_RESET);
  HAL_GPIO_WritePin(AUDIO_GPIO_PINS_9_11_PORT, AUDIO_GPIO_9, GPIO_PIN_RESET);
  HAL_GPIO_WritePin(AUDIO_GPIO_PINS_9_11_PORT, AUDIO_GPIO_10, GPIO_PIN_RESET);
  HAL_GPIO_WritePin(AUDIO_GPIO_PINS_9_11_PORT, AUDIO_GPIO_11, GPIO_PIN_RESET);

  HAL_GPIO_WritePin(AUDIO_GPIO_PIN_12_PORT, AUDIO_GPIO_12, GPIO_PIN_RESET);
  HAL_GPIO_WritePin(AUDIO_GPIO_PINS_13_14_PORT, AUDIO_GPIO_13, GPIO_PIN_RESET);
  HAL_GPIO_WritePin(AUDIO_GPIO_PINS_13_14_PORT, AUDIO_GPIO_14, GPIO_PIN_RESET);
  HAL_GPIO_WritePin(AUDIO_GPIO_PIN_15_PORT, AUDIO_GPIO_15, GPIO_PIN_RESET);

  HAL_GPIO_WritePin(AUDIO_WRITE_AND_ENABLE_GPIO_PORT, AUDIO_WRITE, GPIO_PIN_RESET);
  HAL_GPIO_WritePin(AUDIO_WRITE_AND_ENABLE_GPIO_PORT, AUDIO_ENABLE, GPIO_PIN_SET);

  HAL_GPIO_WritePin(TEST_PIN_GPIO_Port, TEST_PIN_Pin, GPIO_PIN_RESET);
  */

  //128 samples per buffer

#define NUM_VALS 7988
  int vindex = 0;
  //uint16_t values[NUM_VALS];
  const uint16_t* values = ding_pcm;

  //memset(values + 1, 0x00, sizeof(uint16_t) * (NUM_VALS - 2));
  //values[0] = 0x7fff;
    //values[NUM_VALS /2] = 0x3456;
    //values[NUM_VALS - 1] = 0xfeee;

  //memset(values, 0x10//, sizeof(uint16_t) * 64);
  //memset(values + 64, 0x01, sizeof(uint16_t) * 64);

  //char strbuf[64];

  /* USER CODE END 2 */

  /* Infinite loop */
  while (1)
  {

    /* USER CODE BEGIN 3 */

	 /*
	while(vindex <= NUM_VALS)
	{
		uint16_t value = 0;

		//SNSS_GPIO_Port->BSRR = PIN_LOW_BSSR(SNSS_Pin); // nss1 low
		HAL_GPIO_WritePin(SNSS_GPIO_Port, SNSS_Pin, GPIO_PIN_RESET); // NSS1 low
		//GPIO_PinState bit0 = HAL_GPIO_ReadPin(SPI_SNSS_GPIO_Port, SPI_SNSS_Pin);
		//if(audio_ready_bit == GPIO_PIN_RESET){HAL_UART_Transmit(&huart3, (uint8_t*)"\nCS = 0:\n", strlen("\nBit 1 = 0:\n"), 100);}
		//	sprintf(strbuf2, "\nCS = 0:\n", bit0);
		//	HAL_UART_Transmit(&huart3, (uint8_t*)strbuf2, strlen(strbuf2), 100);

		value |= get_spi_byte();
		value |= get_spi_byte() << 8;
		HAL_GPIO_WritePin(SNSS_GPIO_Port, SNSS_Pin, GPIO_PIN_SET); // NSS1 low
		//SNSS_GPIO_Port->BSRR = PIN_HIGH_BSSR; // nss1 high

		//sprintf(strbuf, "%d, ", value);
		//HAL_UART_Transmit(&huart3, (uint8_t*)strbuf, strlen(strbuf), 100);

		values[vindex++] = value;
	}
	*/

	while((DE1_AUDIO_READY_GPIO_Port->IDR & DE1_AUDIO_READY_Pin) == 0);

	//AUDIO_CLEAR_BUF_GPIO_PORT->BSRR = PIN_HIGH_BSSR;
	//AUDIO_CLEAR_BUF_GPIO_PORT->BSRR = PIN_LOW_BSSR(AUDIO_CLEAR_BUF);

	// wait until ready
	//while(AUDIO_READY_GPIO_PORT->IDR & AUDIO_READY == 0);

	//HAL_GPIO_WritePin(AUDIO_CLEAR_BUF_GPIO_PORT, AUDIO_CLEAR_BUF, GPIO_PIN_SET); //set to 0 before sending every NUMVALS
			//HAL_Delay(1000);
	// HAL_GPIO_WritePin(AUDIO_CLEAR_BUF_GPIO_PORT, AUDIO_CLEAR_BUF, GPIO_PIN_RESET);
			//while(HAL_GPIO_ReadPin(AUDIO_READY_GPIO_PORT, AUDIO_READY) != GPIO_PIN_SET);

			for (int i = 0; i < NUM_VALS -4; i += 8){
				/*
				  HAL_GPIO_WritePin(AUDIO_WRITE_AND_ENABLE_GPIO_PORT, AUDIO_WRITE, GPIO_PIN_SET);

				  HAL_GPIO_WritePin(AUDIO_GPIO_PINS_0_3_PORT, AUDIO_GPIO_0, values[i] & 0x01 );
				  HAL_GPIO_WritePin(AUDIO_GPIO_PINS_0_3_PORT, AUDIO_GPIO_1, (values[i] & 0x02) >> 1 );
				  HAL_GPIO_WritePin(AUDIO_GPIO_PINS_0_3_PORT, AUDIO_GPIO_2, (values[i] & 0x04) >> 2);
				  HAL_GPIO_WritePin(AUDIO_GPIO_PINS_0_3_PORT, AUDIO_GPIO_3, (values[i] & 0x08) >> 3);

				  HAL_GPIO_WritePin(AUDIO_GPIO_PINS_4_8_PORT, AUDIO_GPIO_4, (values[i] & 0x10) >> 4);
				  HAL_GPIO_WritePin(AUDIO_GPIO_PINS_4_8_PORT, AUDIO_GPIO_5, (values[i] & 0x20) >> 5);
				  HAL_GPIO_WritePin(AUDIO_GPIO_PINS_4_8_PORT, AUDIO_GPIO_6, (values[i] & 0x40) >> 6);
				  HAL_GPIO_WritePin(AUDIO_GPIO_PINS_4_8_PORT, AUDIO_GPIO_7, (values[i] & 0x80) >> 7);

				  HAL_GPIO_WritePin(AUDIO_GPIO_PINS_4_8_PORT, AUDIO_GPIO_8, (values[i] & 0x100) >> 8);
				  HAL_GPIO_WritePin(AUDIO_GPIO_PINS_9_11_PORT, AUDIO_GPIO_9, (values[i] & 0x200) >> 9);
				  HAL_GPIO_WritePin(AUDIO_GPIO_PINS_9_11_PORT, AUDIO_GPIO_10, (values[i] & 0x400) >> 10);
				  HAL_GPIO_WritePin(AUDIO_GPIO_PINS_9_11_PORT, AUDIO_GPIO_11, (values[i] & 0x800) >> 11);

				  HAL_GPIO_WritePin(AUDIO_GPIO_PIN_12_PORT, AUDIO_GPIO_12, (values[i] & 0x1000) >> 12);
				  HAL_GPIO_WritePin(AUDIO_GPIO_PINS_13_14_PORT, AUDIO_GPIO_13, (values[i] & 0x2000) >> 13);
				  HAL_GPIO_WritePin(AUDIO_GPIO_PINS_13_14_PORT, AUDIO_GPIO_14, (values[i] & 0x4000) >> 14);
				  HAL_GPIO_WritePin(AUDIO_GPIO_PIN_15_PORT, AUDIO_GPIO_15, (values[i] & 0x8000) >> 15);

				  HAL_Delay(1000);
				  HAL_GPIO_WritePin(AUDIO_WRITE_AND_ENABLE_GPIO_PORT, AUDIO_WRITE, GPIO_PIN_RESET);
				  */
				  //HAL_Delay(50);

				//DE1_AUDIO_WR_GPIO_Port->BSRR = PIN_HIGH_BSSR(DE1_AUDIO_WR_Pin);
				GPIOF->ODR = values[i];
				//DE1_AUDIO_WR_GPIO_Port->BSRR = PIN_LOW_BSSR(DE1_AUDIO_WR_Pin);

				//DE1_AUDIO_WR_GPIO_Port->BSRR = PIN_HIGH_BSSR(DE1_AUDIO_WR_Pin);
				GPIOF->ODR = values[i + 1];
				//DE1_AUDIO_WR_GPIO_Port->BSRR = PIN_LOW_BSSR(DE1_AUDIO_WR_Pin);

				//DE1_AUDIO_WR_GPIO_Port->BSRR = PIN_HIGH_BSSR(DE1_AUDIO_WR_Pin);
				GPIOF->ODR = values[i + 2];
				//DE1_AUDIO_WR_GPIO_Port->BSRR = PIN_LOW_BSSR(DE1_AUDIO_WR_Pin);

				//DE1_AUDIO_WR_GPIO_Port->BSRR = PIN_HIGH_BSSR(DE1_AUDIO_WR_Pin);
				GPIOF->ODR = values[i + 3];
				//DE1_AUDIO_WR_GPIO_Port->BSRR = PIN_LOW_BSSR(DE1_AUDIO_WR_Pin);

				//DE1_AUDIO_WR_GPIO_Port->BSRR = PIN_HIGH_BSSR(DE1_AUDIO_WR_Pin);
				GPIOF->ODR = values[i + 4];
				//DE1_AUDIO_WR_GPIO_Port->BSRR = PIN_LOW_BSSR(DE1_AUDIO_WR_Pin);

				//DE1_AUDIO_WR_GPIO_Port->BSRR = PIN_HIGH_BSSR(DE1_AUDIO_WR_Pin);
				GPIOF->ODR = values[i + 5];
				//DE1_AUDIO_WR_GPIO_Port->BSRR = PIN_LOW_BSSR(DE1_AUDIO_WR_Pin);

				//DE1_AUDIO_WR_GPIO_Port->BSRR = PIN_HIGH_BSSR(DE1_AUDIO_WR_Pin);
				GPIOF->ODR = values[i + 6];
				//DE1_AUDIO_WR_GPIO_Port->BSRR = PIN_LOW_BSSR(DE1_AUDIO_WR_Pin);

				//DE1_AUDIO_WR_GPIO_Port->BSRR = PIN_HIGH_BSSR(DE1_AUDIO_WR_Pin);
				GPIOF->ODR = values[i + 7];
				//DE1_AUDIO_WR_GPIO_Port->BSRR = PIN_LOW_BSSR(DE1_AUDIO_WR_Pin);
			}

			//vindex = 0;

	//bit0 = HAL_GPIO_ReadPin(SPI_SNSS_GPIO_Port, SPI_SNSS_Pin);
	//if(audio_ready_bit == GPIO_PIN_RESET){HAL_UART_Transmit(&huart3, (uint8_t*)"\nCS = 0:\n", strlen("\nBit 1 = 0:\n"), 100);}
	//sprintf(strbuf2, "\nCS = 0:\n", bit0);
	//HAL_UART_Transmit(&huart3, (uint8_t*)strbuf2, strlen(strbuf2), 100);

		//HAL_UART_Transmit(&huart3, (uint8_t*)"\n\nBegin:\n", strlen("\n\nBegin:\n"), 100);
		//CDC_Transmit_FS((uint8_t*)"\n\nBegin:\n", strlen("\n\nBegin:\n"));

		//for (int i = 0; i < NUM_VALS; ++i)
		//	strindex += sprintf(strbuf + strindex, "%d, ", values[i]);

		//HAL_UART_Transmit(&huart3, (uint8_t*)strbuf, strindex, 100);
		//CDC_Transmit_FS((uint8_t*)strbuf, strindex);

		//write buffer to GPIO pins

	//GPIO_PinState audio_ready_bit = HAL_GPIO_ReadPin(AUDIO_READY_GPIO_PORT, AUDIO_READY);

	//GPIO_PinState bit0 = HAL_GPIO_ReadPin(AUDIO_GPIO_PINS_0_3_PORT, AUDIO_GPIO_0);

	/*
	GPIO_PinState bit3 = HAL_GPIO_ReadPin(TEST_GPIO_Port_1, GPIO_PIN_5);
	GPIO_PinState bit4 = HAL_GPIO_ReadPin(TEST_GPIO_Port_1, GPIO_PIN_4);

	GPIO_PinState bit5 = HAL_GPIO_ReadPin(TEST_GPIO_Port_2, GPIO_PIN_2);
	GPIO_PinState bit6 = HAL_GPIO_ReadPin(TEST_GPIO_Port_2, GPIO_PIN_4);
	GPIO_PinState bit7 = HAL_GPIO_ReadPin(TEST_GPIO_Port_2, GPIO_PIN_5);
	GPIO_PinState bit8 = HAL_GPIO_ReadPin(TEST_GPIO_Port_2, GPIO_PIN_6);
	*/

	//if(audio_ready_bit == GPIO_PIN_RESET){HAL_UART_Transmit(&huart3, (uint8_t*)"\nAudio Ready = 0:\n", strlen("\nBit 1 = 0:\n"), 100);}
	//if(bit0 == GPIO_PIN_RESET){HAL_UART_Transmit(&huart3, (uint8_t*)"\nBit 0 = 0:\n", strlen("\nBit 1 = 0:\n"), 100);}
	//HAL_Delay(0);

  }

  /* USER CODE END 3 */
}

void SystemClock_Config(void)
{
  RCC_OscInitTypeDef RCC_OscInitStruct = {0};
  RCC_ClkInitTypeDef RCC_ClkInitStruct = {0};

  /** Configure the main internal regulator output voltage
  */
  __HAL_RCC_PWR_CLK_ENABLE();
  __HAL_PWR_VOLTAGESCALING_CONFIG(PWR_REGULATOR_VOLTAGE_SCALE1);

  /** Initializes the RCC Oscillators according to the specified parameters
  * in the RCC_OscInitTypeDef structure.
  */
  RCC_OscInitStruct.OscillatorType = RCC_OSCILLATORTYPE_HSE;
  RCC_OscInitStruct.HSEState = RCC_HSE_BYPASS;
  RCC_OscInitStruct.PLL.PLLState = RCC_PLL_ON;
  RCC_OscInitStruct.PLL.PLLSource = RCC_PLLSOURCE_HSE;
  RCC_OscInitStruct.PLL.PLLM = 4;
  RCC_OscInitStruct.PLL.PLLN = 168;
  RCC_OscInitStruct.PLL.PLLP = RCC_PLLP_DIV2;
  RCC_OscInitStruct.PLL.PLLQ = 7;
  RCC_OscInitStruct.PLL.PLLR = 2;
  if (HAL_RCC_OscConfig(&RCC_OscInitStruct) != HAL_OK)
  {
    Error_Handler();
  }

  /** Initializes the CPU, AHB and APB buses clocks
  */
  RCC_ClkInitStruct.ClockType = RCC_CLOCKTYPE_HCLK|RCC_CLOCKTYPE_SYSCLK
                              |RCC_CLOCKTYPE_PCLK1|RCC_CLOCKTYPE_PCLK2;
  RCC_ClkInitStruct.SYSCLKSource = RCC_SYSCLKSOURCE_PLLCLK;
  RCC_ClkInitStruct.AHBCLKDivider = RCC_SYSCLK_DIV1;
  RCC_ClkInitStruct.APB1CLKDivider = RCC_HCLK_DIV4;
  RCC_ClkInitStruct.APB2CLKDivider = RCC_HCLK_DIV2;

  if (HAL_RCC_ClockConfig(&RCC_ClkInitStruct, FLASH_LATENCY_5) != HAL_OK)
  {
    Error_Handler();
  }
}

static void MX_SPI1_Init(void)
{

  /* SPI1 parameter configuration*/
  hspi1.Instance = SPI1;
  hspi1.Init.Mode = SPI_MODE_MASTER;
  hspi1.Init.Direction = SPI_DIRECTION_2LINES_RXONLY;
  hspi1.Init.DataSize = SPI_DATASIZE_8BIT;
  hspi1.Init.CLKPolarity = SPI_POLARITY_LOW;
  hspi1.Init.CLKPhase = SPI_PHASE_1EDGE;
  hspi1.Init.NSS = SPI_NSS_SOFT;
  hspi1.Init.BaudRatePrescaler = SPI_BAUDRATEPRESCALER_4;
  hspi1.Init.FirstBit = SPI_FIRSTBIT_MSB;
  hspi1.Init.TIMode = SPI_TIMODE_DISABLE;
  hspi1.Init.CRCCalculation = SPI_CRCCALCULATION_DISABLE;
  hspi1.Init.CRCPolynomial = 10;
  if (HAL_SPI_Init(&hspi1) != HAL_OK)
  {
    Error_Handler();
  }

}

static void MX_TIM1_Init(void)
{

  TIM_ClockConfigTypeDef sClockSourceConfig = {0};
  TIM_MasterConfigTypeDef sMasterConfig = {0};
  TIM_OC_InitTypeDef sConfigOC = {0};
  TIM_BreakDeadTimeConfigTypeDef sBreakDeadTimeConfig = {0};

  htim1.Instance = TIM1;
  htim1.Init.Prescaler = 0;
  htim1.Init.CounterMode = TIM_COUNTERMODE_UP;
  htim1.Init.Period = 5;
  htim1.Init.ClockDivision = TIM_CLOCKDIVISION_DIV1;
  htim1.Init.RepetitionCounter = 0;
  htim1.Init.AutoReloadPreload = TIM_AUTORELOAD_PRELOAD_ENABLE;
  if (HAL_TIM_Base_Init(&htim1) != HAL_OK)
  {
    Error_Handler();
  }
  sClockSourceConfig.ClockSource = TIM_CLOCKSOURCE_INTERNAL;
  if (HAL_TIM_ConfigClockSource(&htim1, &sClockSourceConfig) != HAL_OK)
  {
    Error_Handler();
  }
  if (HAL_TIM_PWM_Init(&htim1) != HAL_OK)
  {
    Error_Handler();
  }
  sMasterConfig.MasterOutputTrigger = TIM_TRGO_RESET;
  sMasterConfig.MasterSlaveMode = TIM_MASTERSLAVEMODE_DISABLE;
  if (HAL_TIMEx_MasterConfigSynchronization(&htim1, &sMasterConfig) != HAL_OK)
  {
    Error_Handler();
  }
  sConfigOC.OCMode = TIM_OCMODE_PWM1;
  sConfigOC.Pulse = 10;
  sConfigOC.OCPolarity = TIM_OCPOLARITY_HIGH;
  sConfigOC.OCNPolarity = TIM_OCNPOLARITY_HIGH;
  sConfigOC.OCFastMode = TIM_OCFAST_DISABLE;
  sConfigOC.OCIdleState = TIM_OCIDLESTATE_RESET;
  sConfigOC.OCNIdleState = TIM_OCNIDLESTATE_RESET;
  if (HAL_TIM_PWM_ConfigChannel(&htim1, &sConfigOC, TIM_CHANNEL_1) != HAL_OK)
  {
    Error_Handler();
  }
  sBreakDeadTimeConfig.OffStateRunMode = TIM_OSSR_DISABLE;
  sBreakDeadTimeConfig.OffStateIDLEMode = TIM_OSSI_DISABLE;
  sBreakDeadTimeConfig.LockLevel = TIM_LOCKLEVEL_OFF;
  sBreakDeadTimeConfig.DeadTime = 0;
  sBreakDeadTimeConfig.BreakState = TIM_BREAK_DISABLE;
  sBreakDeadTimeConfig.BreakPolarity = TIM_BREAKPOLARITY_HIGH;
  sBreakDeadTimeConfig.AutomaticOutput = TIM_AUTOMATICOUTPUT_DISABLE;
  if (HAL_TIMEx_ConfigBreakDeadTime(&htim1, &sBreakDeadTimeConfig) != HAL_OK)
  {
    Error_Handler();
  }
  HAL_TIM_MspPostInit(&htim1);

}

static void MX_USART3_UART_Init(void)
{

  huart3.Instance = USART3;
  huart3.Init.BaudRate = 115200;
  huart3.Init.WordLength = UART_WORDLENGTH_8B;
  huart3.Init.StopBits = UART_STOPBITS_1;
  huart3.Init.Parity = UART_PARITY_NONE;
  huart3.Init.Mode = UART_MODE_TX_RX;
  huart3.Init.HwFlowCtl = UART_HWCONTROL_NONE;
  huart3.Init.OverSampling = UART_OVERSAMPLING_16;
  if (HAL_UART_Init(&huart3) != HAL_OK)
  {
    Error_Handler();
  }

}

static void MX_GPIO_Init(void)
{
  GPIO_InitTypeDef GPIO_InitStruct = {0};

  /* GPIO Ports Clock Enable */
  __HAL_RCC_GPIOC_CLK_ENABLE();
  __HAL_RCC_GPIOF_CLK_ENABLE();
  __HAL_RCC_GPIOH_CLK_ENABLE();
  __HAL_RCC_GPIOA_CLK_ENABLE();
  __HAL_RCC_GPIOB_CLK_ENABLE();
  __HAL_RCC_GPIOE_CLK_ENABLE();
  __HAL_RCC_GPIOD_CLK_ENABLE();

  /*Configure GPIO pin Output Level */
  HAL_GPIO_WritePin(GPIOF, AUDIO0_Pin|AUDIO1_Pin|AUDIO2_Pin|AUDIO3_Pin
                          |AUDIO4_Pin|AUDIO5_Pin|AUDIO6_Pin|AUDIO7_Pin
                          |AUDIO8_Pin|AUDIO9_Pin|AUDIO10_Pin|AUDIO11_Pin
                          |AUDIO12_Pin|AUDIO13_Pin|AUDIO14_Pin|AUDIO15_Pin, GPIO_PIN_RESET);

  /*Configure GPIO pin Output Level */
  HAL_GPIO_WritePin(GPIOB, LD1_Pin|DE1_AUDIO_WR_Pin|LD3_Pin|LD2_Pin, GPIO_PIN_RESET);

  /*Configure GPIO pin Output Level */
  HAL_GPIO_WritePin(SNSS_GPIO_Port, SNSS_Pin, GPIO_PIN_RESET);

  /*Configure GPIO pin : USER_Btn_Pin */
  GPIO_InitStruct.Pin = USER_Btn_Pin;
  GPIO_InitStruct.Mode = GPIO_MODE_IT_RISING;
  GPIO_InitStruct.Pull = GPIO_NOPULL;
  HAL_GPIO_Init(USER_Btn_GPIO_Port, &GPIO_InitStruct);

  /*Configure GPIO pins : AUDIO0_Pin AUDIO1_Pin AUDIO2_Pin AUDIO3_Pin
                           AUDIO4_Pin AUDIO5_Pin AUDIO6_Pin AUDIO7_Pin
                           AUDIO8_Pin AUDIO9_Pin AUDIO10_Pin AUDIO11_Pin
                           AUDIO12_Pin AUDIO13_Pin AUDIO14_Pin AUDIO15_Pin */
  GPIO_InitStruct.Pin = AUDIO0_Pin|AUDIO1_Pin|AUDIO2_Pin|AUDIO3_Pin
                          |AUDIO4_Pin|AUDIO5_Pin|AUDIO6_Pin|AUDIO7_Pin
                          |AUDIO8_Pin|AUDIO9_Pin|AUDIO10_Pin|AUDIO11_Pin
                          |AUDIO12_Pin|AUDIO13_Pin|AUDIO14_Pin|AUDIO15_Pin;
  GPIO_InitStruct.Mode = GPIO_MODE_OUTPUT_OD;
  GPIO_InitStruct.Pull = GPIO_NOPULL;
  GPIO_InitStruct.Speed = GPIO_SPEED_FREQ_VERY_HIGH;
  HAL_GPIO_Init(GPIOF, &GPIO_InitStruct);

  /*Configure GPIO pins : LD1_Pin LD3_Pin LD2_Pin */
  GPIO_InitStruct.Pin = LD1_Pin|LD3_Pin|LD2_Pin;
  GPIO_InitStruct.Mode = GPIO_MODE_OUTPUT_PP;
  GPIO_InitStruct.Pull = GPIO_NOPULL;
  GPIO_InitStruct.Speed = GPIO_SPEED_FREQ_LOW;
  HAL_GPIO_Init(GPIOB, &GPIO_InitStruct);

  /*Configure GPIO pin : SNSS_Pin */
  GPIO_InitStruct.Pin = SNSS_Pin;
  GPIO_InitStruct.Mode = GPIO_MODE_OUTPUT_OD;
  GPIO_InitStruct.Pull = GPIO_NOPULL;
  GPIO_InitStruct.Speed = GPIO_SPEED_FREQ_LOW;
  HAL_GPIO_Init(SNSS_GPIO_Port, &GPIO_InitStruct);

  /*Configure GPIO pin : DE1_AUDIO_WR_Pin */
  GPIO_InitStruct.Pin = DE1_AUDIO_WR_Pin;
  GPIO_InitStruct.Mode = GPIO_MODE_OUTPUT_OD;
  GPIO_InitStruct.Pull = GPIO_NOPULL;
  GPIO_InitStruct.Speed = GPIO_SPEED_FREQ_VERY_HIGH;
  HAL_GPIO_Init(DE1_AUDIO_WR_GPIO_Port, &GPIO_InitStruct);

  /*Configure GPIO pin : DE1_AUDIO_READY_Pin */
  GPIO_InitStruct.Pin = DE1_AUDIO_READY_Pin;
  GPIO_InitStruct.Mode = GPIO_MODE_INPUT;
  GPIO_InitStruct.Pull = GPIO_NOPULL;
  HAL_GPIO_Init(DE1_AUDIO_READY_GPIO_Port, &GPIO_InitStruct);

  /*Configure GPIO pins : USB_SOF_Pin USB_ID_Pin USB_DM_Pin USB_DP_Pin */
  GPIO_InitStruct.Pin = USB_SOF_Pin|USB_ID_Pin|USB_DM_Pin|USB_DP_Pin;
  GPIO_InitStruct.Mode = GPIO_MODE_AF_PP;
  GPIO_InitStruct.Pull = GPIO_NOPULL;
  GPIO_InitStruct.Speed = GPIO_SPEED_FREQ_VERY_HIGH;
  GPIO_InitStruct.Alternate = GPIO_AF10_OTG_FS;
  HAL_GPIO_Init(GPIOA, &GPIO_InitStruct);

  /*Configure GPIO pin : USB_VBUS_Pin */
  GPIO_InitStruct.Pin = USB_VBUS_Pin;
  GPIO_InitStruct.Mode = GPIO_MODE_INPUT;
  GPIO_InitStruct.Pull = GPIO_NOPULL;
  HAL_GPIO_Init(USB_VBUS_GPIO_Port, &GPIO_InitStruct);

}

void Error_Handler(void)
{
  __disable_irq();
  while (1)
  {
  }
}
